VERSION ""

NS_ :

BS_:

BU_: TC CGM VCU TOOL

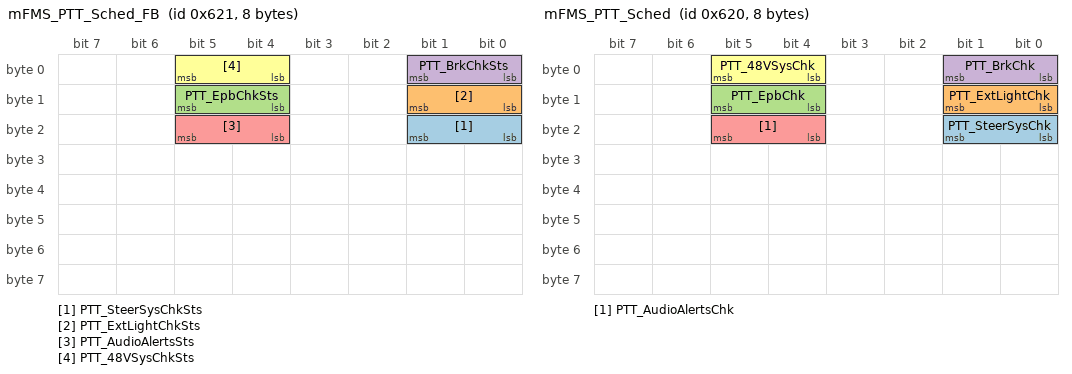
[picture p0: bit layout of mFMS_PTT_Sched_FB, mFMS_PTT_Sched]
BO_ 1569 mFMS_PTT_Sched_FB: 8 VCU
 SG_ PTT_SteerSysChkSts : 17|2@0+ (1,0) [0|3] ""  CGM
 SG_ PTT_ExtLightChkSts : 9|2@0+ (1,0) [0|3] ""  CGM
 SG_ PTT_EpbChkSts : 13|2@0+ (1,0) [0|3] ""  CGM
 SG_ PTT_BrkChkSts : 1|2@0+ (1,0) [0|3] ""  CGM
 SG_ PTT_AudioAlertsSts : 21|2@0+ (1,0) [0|3] ""  CGM
 SG_ PTT_48VSysChkSts : 5|2@0+ (1,0) [0|3] ""  CGM

BO_ 1568 mFMS_PTT_Sched: 8 CGM
 SG_ PTT_SteerSysChk : 17|2@0+ (1,0) [0|3] ""  VCU
 SG_ PTT_ExtLightChk : 9|2@0+ (1,0) [0|3] ""  VCU
 SG_ PTT_EpbChk : 13|2@0+ (1,0) [0|3] ""  VCU
 SG_ PTT_BrkChk : 1|2@0+ (1,0) [0|3] ""  VCU
 SG_ PTT_AudioAlertsChk : 21|2@0+ (1,0) [0|3] ""  VCU
 SG_ PTT_48VSysChk : 5|2@0+ (1,0) [0|3] ""  VCU

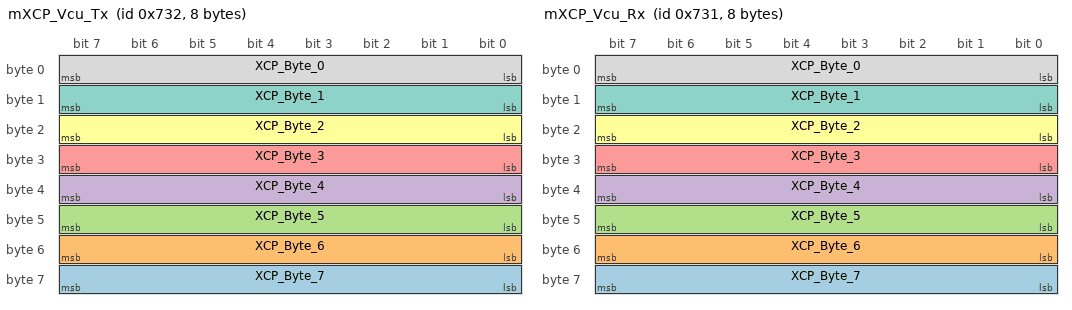
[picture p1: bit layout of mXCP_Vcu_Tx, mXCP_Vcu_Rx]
BO_ 1842 mXCP_Vcu_Tx: 8 VCU
 SG_ XCP_Byte_7 : 63|8@0+ (1,0) [0|0] ""  TOOL
 SG_ XCP_Byte_6 : 55|8@0+ (1,0) [0|0] ""  TOOL
 SG_ XCP_Byte_5 : 47|8@0+ (1,0) [0|0] ""  TOOL
 SG_ XCP_Byte_4 : 39|8@0+ (1,0) [0|0] ""  TOOL
 SG_ XCP_Byte_3 : 31|8@0+ (1,0) [0|0] ""  TOOL
 SG_ XCP_Byte_2 : 23|8@0+ (1,0) [0|0] ""  TOOL
 SG_ XCP_Byte_1 : 15|8@0+ (1,0) [0|0] ""  TOOL
 SG_ XCP_Byte_0 : 7|8@0+ (1,0) [0|0] ""  TOOL

BO_ 1841 mXCP_Vcu_Rx: 8 TOOL
 SG_ XCP_Byte_7 : 63|8@0+ (1,0) [0|0] ""  VCU
 SG_ XCP_Byte_6 : 55|8@0+ (1,0) [0|0] ""  VCU
 SG_ XCP_Byte_5 : 47|8@0+ (1,0) [0|0] ""  VCU
 SG_ XCP_Byte_4 : 39|8@0+ (1,0) [0|0] ""  VCU
 SG_ XCP_Byte_3 : 31|8@0+ (1,0) [0|0] ""  VCU
 SG_ XCP_Byte_2 : 23|8@0+ (1,0) [0|0] ""  VCU
 SG_ XCP_Byte_1 : 15|8@0+ (1,0) [0|0] ""  VCU
 SG_ XCP_Byte_0 : 7|8@0+ (1,0) [0|0] ""  VCU

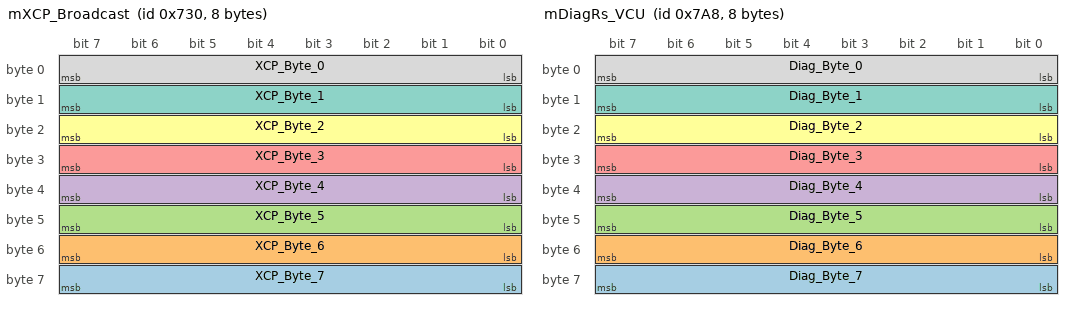
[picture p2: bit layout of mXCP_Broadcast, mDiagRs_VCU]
BO_ 1840 mXCP_Broadcast: 8 TOOL
 SG_ XCP_Byte_7 : 63|8@0+ (1,0) [0|0] ""  VCU
 SG_ XCP_Byte_6 : 55|8@0+ (1,0) [0|0] ""  VCU
 SG_ XCP_Byte_5 : 47|8@0+ (1,0) [0|0] ""  VCU
 SG_ XCP_Byte_4 : 39|8@0+ (1,0) [0|0] ""  VCU
 SG_ XCP_Byte_3 : 31|8@0+ (1,0) [0|0] ""  VCU
 SG_ XCP_Byte_2 : 23|8@0+ (1,0) [0|0] ""  VCU
 SG_ XCP_Byte_1 : 15|8@0+ (1,0) [0|0] ""  VCU
 SG_ XCP_Byte_0 : 7|8@0+ (1,0) [0|0] ""  VCU

BO_ 1960 mDiagRs_VCU: 8 VCU
 SG_ Diag_Byte_7 : 63|8@0+ (1,0) [0|0] ""  TOOL
 SG_ Diag_Byte_6 : 55|8@0+ (1,0) [0|0] ""  TOOL
 SG_ Diag_Byte_5 : 47|8@0+ (1,0) [0|0] ""  TOOL
 SG_ Diag_Byte_4 : 39|8@0+ (1,0) [0|0] ""  TOOL
 SG_ Diag_Byte_3 : 31|8@0+ (1,0) [0|0] ""  TOOL
 SG_ Diag_Byte_2 : 23|8@0+ (1,0) [0|0] ""  TOOL
 SG_ Diag_Byte_1 : 15|8@0+ (1,0) [0|0] ""  TOOL
 SG_ Diag_Byte_0 : 7|8@0+ (1,0) [0|0] ""  TOOL

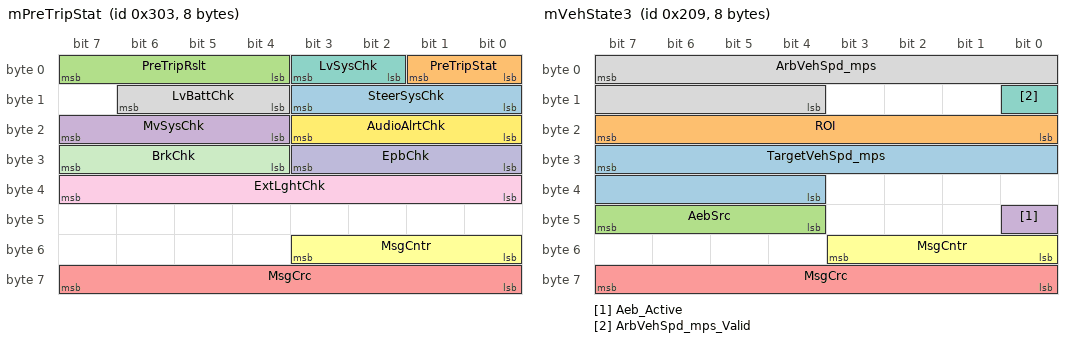
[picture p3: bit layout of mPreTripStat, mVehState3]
BO_ 771 mPreTripStat: 8 VCU
 SG_ SteerSysChk : 11|4@0+ (1,0) [0|15] ""  CGM
 SG_ PreTripStat : 1|2@0+ (1,0) [0|3] ""  CGM
 SG_ PreTripRslt : 7|4@0+ (1,0) [0|15] ""  CGM
 SG_ MvSysChk : 23|4@0+ (1,0) [0|15] ""  CGM
 SG_ MsgCrc : 63|8@0+ (1,0) [0|255] ""  CGM
 SG_ MsgCntr : 51|4@0+ (1,0) [0|15] ""  CGM
 SG_ LvSysChk : 3|2@0+ (1,0) [0|3] ""  CGM
 SG_ LvBattChk : 14|3@0+ (1,0) [0|7] ""  CGM
 SG_ ExtLghtChk : 39|8@0+ (1,0) [0|255] ""  CGM
 SG_ EpbChk : 27|4@0+ (1,0) [0|15] ""  CGM
 SG_ BrkChk : 31|4@0+ (1,0) [0|15] ""  CGM
 SG_ AudioAlrtChk : 19|4@0+ (1,0) [0|15] ""  CGM

BO_ 521 mVehState3: 8 VCU
 SG_ TargetVehSpd_mps : 31|12@0- (0.01,0) [-20.48|20.47] "mps"  CGM
 SG_ ROI : 23|8@0- (0.01,0) [-1.28|1.27] ""  CGM
 SG_ AebSrc : 47|4@0+ (1,0) [0|15] ""  CGM
 SG_ Aeb_Active : 40|1@0+ (1,0) [0|0] ""  CGM
 SG_ MsgCrc : 63|8@0+ (1,0) [0|255] ""  CGM
 SG_ MsgCntr : 51|4@0+ (1,0) [0|15] ""  CGM
 SG_ ArbVehSpd_mps_Valid : 8|1@0+ (1,0) [0|0] ""  CGM
 SG_ ArbVehSpd_mps : 7|12@0- (0.01,0) [-20.48|20.47] "mps"  CGM

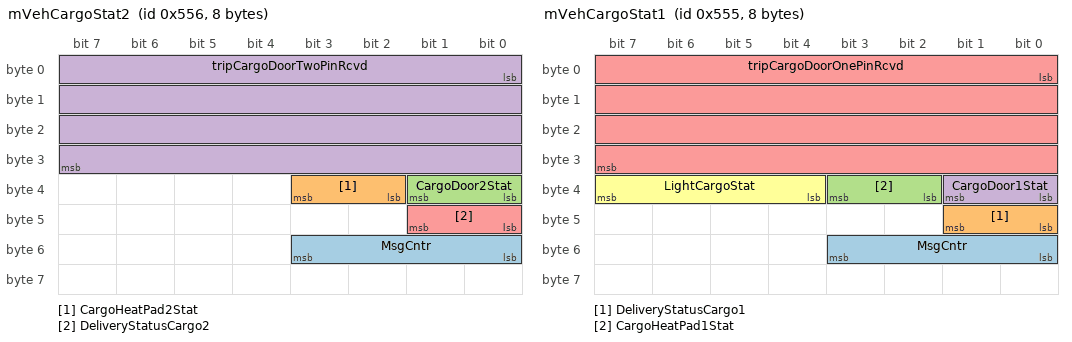
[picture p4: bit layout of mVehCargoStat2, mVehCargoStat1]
BO_ 1366 mVehCargoStat2: 8 VCU
 SG_ MsgCntr : 51|4@0+ (1,0) [0|15] ""  CGM
 SG_ CargoHeatPad2Stat : 35|2@0+ (1,0) [0|3] ""  CGM
 SG_ CargoDoor2Stat : 33|2@0+ (1,0) [0|3] ""  CGM
 SG_ tripCargoDoorTwoPinRcvd : 0|32@1+ (1,0) [0|0] "BCD"  CGM
 SG_ DeliveryStatusCargo2 : 41|2@0+ (1,0) [0|0] ""  CGM

BO_ 1365 mVehCargoStat1: 8 VCU
 SG_ MsgCntr : 51|4@0+ (1,0) [0|15] ""  CGM
 SG_ DeliveryStatusCargo1 : 41|2@0+ (1,0) [0|0] ""  CGM
 SG_ CargoHeatPad1Stat : 35|2@0+ (1,0) [0|3] ""  CGM
 SG_ CargoDoor1Stat : 33|2@0+ (1,0) [0|3] ""  CGM
 SG_ tripCargoDoorOnePinRcvd : 0|32@1+ (1,0) [0|0] "BCD"  CGM
 SG_ LightCargoStat : 39|4@0+ (1,0) [0|15] ""  CGM

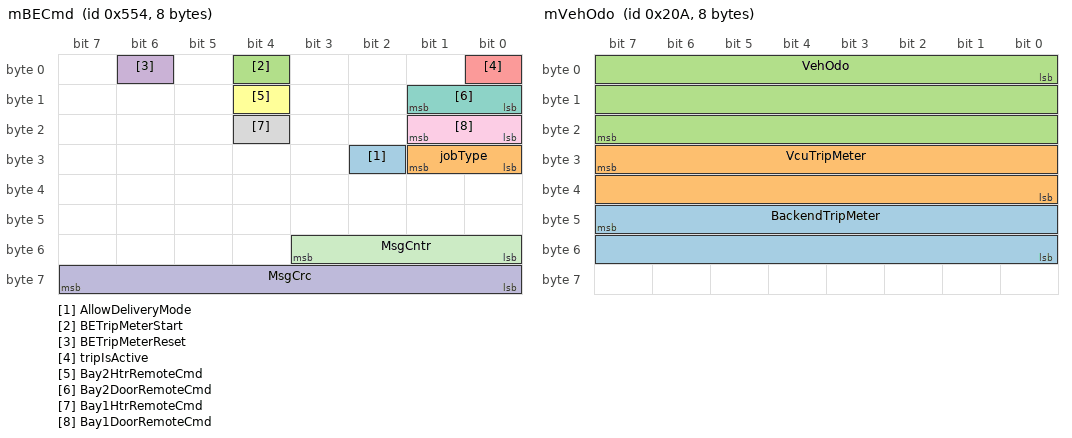
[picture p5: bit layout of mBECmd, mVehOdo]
BO_ 1364 mBECmd: 8 CGM
 SG_ AllowDeliveryMode : 26|1@0+ (1,0) [0|1] ""  VCU
 SG_ jobType : 25|2@0+ (1,0) [0|3] ""  VCU
 SG_ BETripMeterStart : 4|1@0+ (1,0) [0|0] ""  VCU
 SG_ BETripMeterReset : 6|1@0+ (1,0) [0|0] ""  VCU
 SG_ tripIsActive : 0|1@0+ (1,0) [0|0] ""  VCU
 SG_ Bay2HtrRemoteCmd : 12|1@0+ (1,0) [0|1] ""  VCU
 SG_ Bay2DoorRemoteCmd : 9|2@0+ (1,0) [0|3] ""  VCU
 SG_ Bay1HtrRemoteCmd : 20|1@0+ (1,0) [0|1] ""  VCU
 SG_ Bay1DoorRemoteCmd : 17|2@0+ (1,0) [0|3] ""  VCU
 SG_ MsgCrc : 63|8@0+ (1,0) [0|255] ""  VCU
 SG_ MsgCntr : 51|4@0+ (1,0) [0|15] ""  VCU

BO_ 1363 mBECargoPIN: 8 CGM
 SG_ tripCargoDoorTwoPin : 32|32@1+ (1,0) [0|0] "BCD"  VCU
 SG_ tripCargoDoorOnePin : 0|32@1+ (1,0) [0|0] "BCD"  VCU

BO_ 522 mVehOdo: 8 VCU
 SG_ BackendTripMeter : 47|16@0+ (0.001,0) [0|65.535] "Km"  CGM
 SG_ VcuTripMeter : 31|16@0+ (0.001,0) [0|65.535] "Km"  CGM
 SG_ VehOdo : 0|24@1+ (0.001,0) [0|16777.213] "Km"  CGM

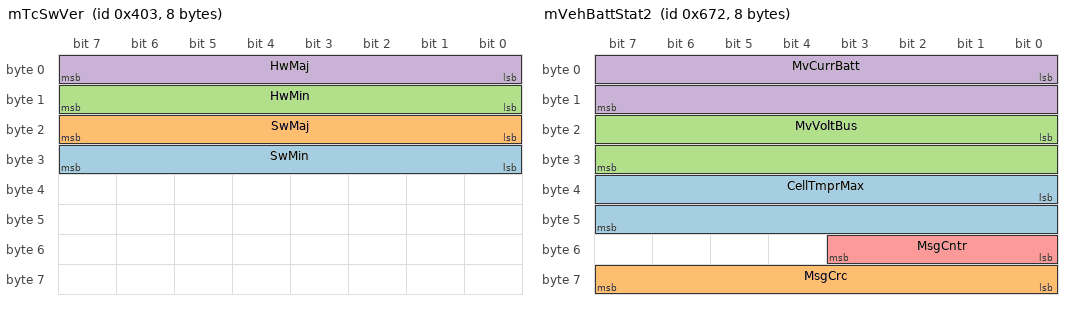
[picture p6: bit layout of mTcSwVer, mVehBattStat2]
BO_ 1027 mTcSwVer: 8 TC
 SG_ SwMin : 31|8@0+ (1,0) [0|255] ""  VCU
 SG_ SwMaj : 23|8@0+ (1,0) [0|255] ""  VCU
 SG_ HwMin : 15|8@0+ (1,0) [0|255] ""  VCU
 SG_ HwMaj : 7|8@0+ (1,0) [0|255] ""  VCU

BO_ 1650 mVehBattStat2: 8 VCU
 SG_ CellTmprMax : 32|16@1+ (0.03125,-273) [-273|1734.96875] "degC"  CGM
 SG_ MsgCrc : 63|8@0+ (1,0) [0|255] ""  CGM
 SG_ MvVoltBus : 16|16@1+ (0.05,0) [0|3212.75] "V"  CGM
 SG_ MvCurrBatt : 0|16@1+ (0.05,-1600) [-1600|1612.75] "A"  CGM
 SG_ MsgCntr : 51|4@0+ (1,0) [0|15] ""  CGM

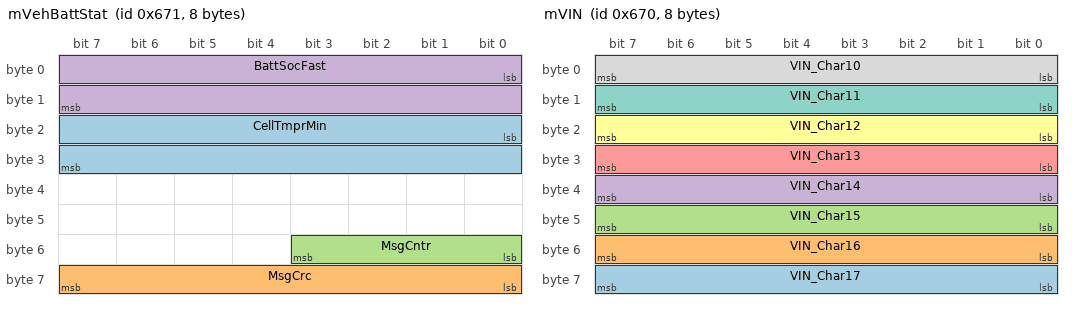
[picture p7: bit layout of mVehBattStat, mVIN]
BO_ 1649 mVehBattStat: 8 VCU
 SG_ CellTmprMin : 16|16@1+ (0.03125,-273) [-273|1734.96875] "degC"  CGM
 SG_ MsgCrc : 63|8@0+ (1,0) [0|255] ""  CGM
 SG_ MsgCntr : 51|4@0+ (1,0) [0|15] ""  CGM
 SG_ BattSocFast : 0|16@1+ (0.0015625,0) [0|100.3984375] "%"  CGM

BO_ 1648 mVIN: 8 VCU
 SG_ VIN_Char17 : 63|8@0+ (1,0) [0|255] "ASCII"  CGM
 SG_ VIN_Char16 : 55|8@0+ (1,0) [0|255] "ASCII"  CGM
 SG_ VIN_Char15 : 47|8@0+ (1,0) [0|255] "ASCII"  CGM
 SG_ VIN_Char14 : 39|8@0+ (1,0) [0|255] "ASCII"  CGM
 SG_ VIN_Char13 : 31|8@0+ (1,0) [0|255] "ASCII"  CGM
 SG_ VIN_Char12 : 23|8@0+ (1,0) [0|255] "ASCII"  CGM
 SG_ VIN_Char11 : 15|8@0+ (1,0) [0|255] "ASCII"  CGM
 SG_ VIN_Char10 : 7|8@0+ (1,0) [0|255] "ASCII"  CGM

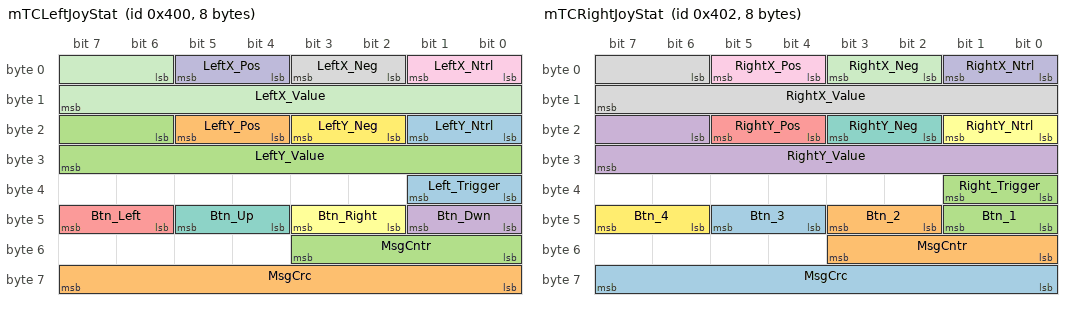
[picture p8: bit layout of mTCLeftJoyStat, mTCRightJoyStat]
BO_ 1024 mTCLeftJoyStat: 8 TC
 SG_ Left_Trigger : 32|2@1+ (1,0) [0|3] ""  VCU
 SG_ MsgCrc : 63|8@0+ (1,0) [0|255] ""  VCU
 SG_ MsgCntr : 51|4@0+ (1,0) [0|15] ""  VCU
 SG_ Btn_Dwn : 40|2@1+ (1,0) [0|3] ""  VCU
 SG_ Btn_Left : 46|2@1+ (1,0) [0|3] ""  VCU
 SG_ Btn_Right : 42|2@1+ (1,0) [0|3] ""  VCU
 SG_ Btn_Up : 44|2@1+ (1,0) [0|3] ""  VCU
 SG_ LeftX_Neg : 2|2@1+ (1,0) [0|3] ""  VCU
 SG_ LeftX_Ntrl : 0|2@1+ (1,0) [0|3] ""  VCU
 SG_ LeftX_Pos : 4|2@1+ (1,0) [0|3] ""  VCU
 SG_ LeftX_Value : 6|10@1+ (1,0) [0|1023] ""  VCU
 SG_ LeftY_Neg : 18|2@1+ (1,0) [0|3] ""  VCU
 SG_ LeftY_Ntrl : 16|2@1+ (1,0) [0|3] ""  VCU
 SG_ LeftY_Pos : 20|2@1+ (1,0) [0|3] ""  VCU
 SG_ LeftY_Value : 22|10@1+ (1,0) [0|1023] ""  VCU

BO_ 1026 mTCRightJoyStat: 8 TC
 SG_ MsgCrc : 63|8@0+ (1,0) [0|255] ""  VCU
 SG_ MsgCntr : 51|4@0+ (1,0) [0|15] ""  VCU
 SG_ Right_Trigger : 32|2@1+ (1,0) [0|3] ""  VCU
 SG_ RightY_Value : 22|10@1+ (1,0) [0|1023] ""  VCU
 SG_ RightY_Pos : 20|2@1+ (1,0) [0|3] ""  VCU
 SG_ RightY_Ntrl : 16|2@1+ (1,0) [0|3] ""  VCU
 SG_ RightY_Neg : 18|2@1+ (1,0) [0|3] ""  VCU
 SG_ RightX_Value : 6|10@1+ (1,0) [0|1023] ""  VCU
 SG_ RightX_Pos : 4|2@1+ (1,0) [0|3] ""  VCU
 SG_ RightX_Ntrl : 0|2@1+ (1,0) [0|3] ""  VCU
 SG_ RightX_Neg : 2|2@1+ (1,0) [0|3] ""  VCU
 SG_ Btn_4 : 46|2@1+ (1,0) [0|3] ""  VCU
 SG_ Btn_3 : 44|2@1+ (1,0) [0|3] ""  VCU
 SG_ Btn_2 : 42|2@1+ (1,0) [0|3] ""  VCU
 SG_ Btn_1 : 40|2@1+ (1,0) [0|3] ""  VCU

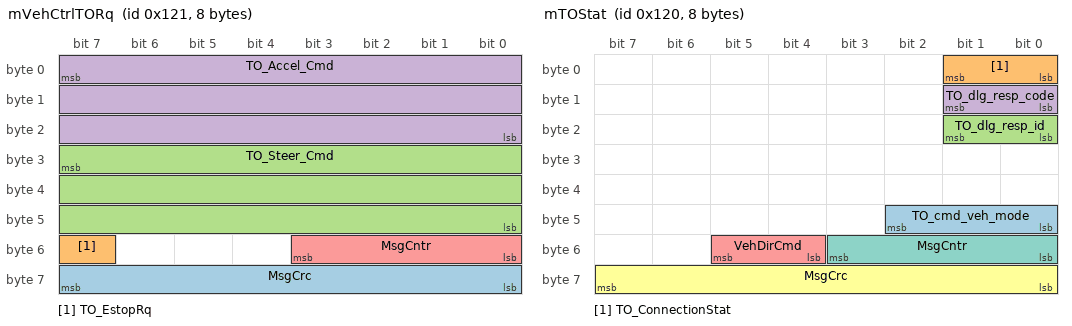
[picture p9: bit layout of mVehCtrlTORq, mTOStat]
BO_ 289 mVehCtrlTORq: 8 CGM
 SG_ MsgCrc : 63|8@0+ (1,0) [0|255] ""  VCU
 SG_ TO_EstopRq : 55|1@0+ (1,0) [0|1] ""  VCU
 SG_ TO_Steer_Cmd : 31|24@0- (1E-06,0) [-1|1] ""  VCU
 SG_ TO_Accel_Cmd : 7|24@0- (1E-06,0) [-1|1] ""  VCU
 SG_ MsgCntr : 51|4@0+ (1,0) [0|15] ""  VCU

BO_ 288 mTOStat: 8 CGM
 SG_ TO_cmd_veh_mode : 42|3@0+ (1,0) [0|7] ""  VCU
 SG_ TO_ConnectionStat : 1|2@0+ (1,0) [0|2] ""  VCU
 SG_ TO_dlg_resp_id : 17|2@0+ (1,0) [0|3] ""  VCU
 SG_ TO_dlg_resp_code : 9|2@0+ (1,0) [0|3] ""  VCU
 SG_ VehDirCmd : 53|2@0+ (1,0) [0|0] ""  VCU
 SG_ MsgCrc : 63|8@0+ (1,0) [0|255] ""  VCU
 SG_ MsgCntr : 51|4@0+ (1,0) [0|15] ""  VCU

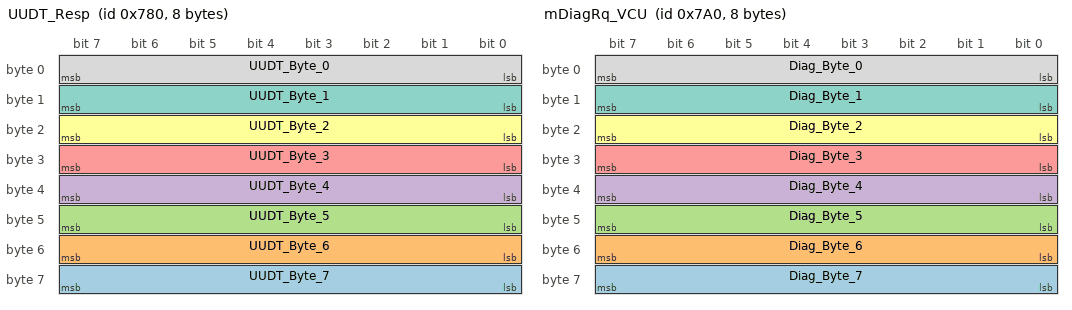
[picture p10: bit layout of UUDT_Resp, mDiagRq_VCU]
BO_ 1920 UUDT_Resp: 8 VCU
 SG_ UUDT_Byte_7 : 63|8@0+ (1,0) [0|0] ""  TOOL
 SG_ UUDT_Byte_6 : 55|8@0+ (1,0) [0|0] ""  TOOL
 SG_ UUDT_Byte_5 : 47|8@0+ (1,0) [0|0] ""  TOOL
 SG_ UUDT_Byte_4 : 39|8@0+ (1,0) [0|0] ""  TOOL
 SG_ UUDT_Byte_3 : 31|8@0+ (1,0) [0|0] ""  TOOL
 SG_ UUDT_Byte_2 : 23|8@0+ (1,0) [0|0] ""  TOOL
 SG_ UUDT_Byte_1 : 15|8@0+ (1,0) [0|0] ""  TOOL
 SG_ UUDT_Byte_0 : 7|8@0+ (1,0) [0|0] ""  TOOL

BO_ 1952 mDiagRq_VCU: 8 TOOL
 SG_ Diag_Byte_7 : 63|8@0+ (1,0) [0|0] ""  VCU
 SG_ Diag_Byte_6 : 55|8@0+ (1,0) [0|0] ""  VCU
 SG_ Diag_Byte_5 : 47|8@0+ (1,0) [0|0] ""  VCU
 SG_ Diag_Byte_4 : 39|8@0+ (1,0) [0|0] ""  VCU
 SG_ Diag_Byte_3 : 31|8@0+ (1,0) [0|0] ""  VCU
 SG_ Diag_Byte_2 : 23|8@0+ (1,0) [0|0] ""  VCU
 SG_ Diag_Byte_1 : 15|8@0+ (1,0) [0|0] ""  VCU
 SG_ Diag_Byte_0 : 7|8@0+ (1,0) [0|0] ""  VCU

BO_ 1160 mVcuHeartbeat: 8 VCU
 SG_ seconds : 7|32@0- (1,0) [-2147483648|2147483647] "s"  CGM
 SG_ nanoseconds : 39|32@0+ (1,0) [0|4294967295] "ns"  CGM

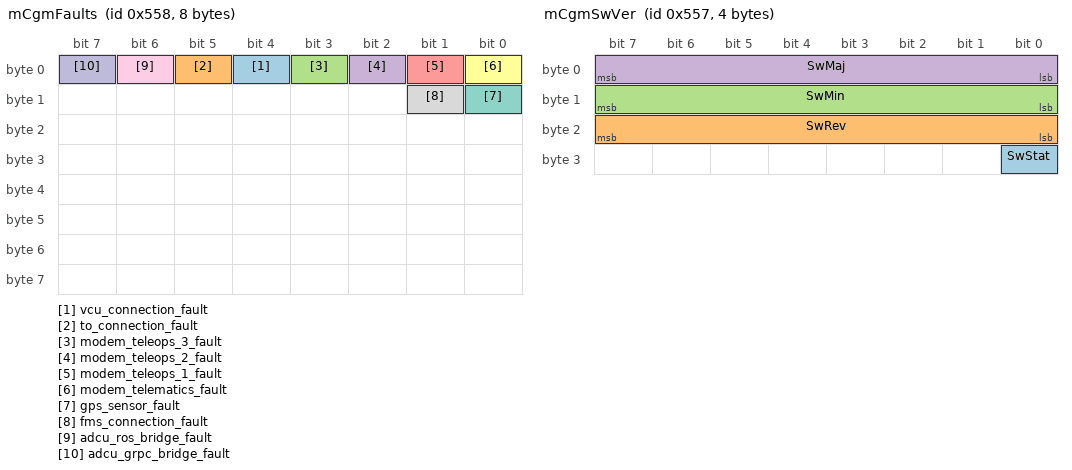
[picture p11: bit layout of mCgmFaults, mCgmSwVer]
BO_ 1368 mCgmFaults: 8 CGM
 SG_ vcu_connection_fault : 4|1@0+ (1,0) [0|0] ""  VCU
 SG_ to_connection_fault : 5|1@0+ (1,0) [0|0] ""  VCU
 SG_ modem_teleops_3_fault : 3|1@0+ (1,0) [0|0] ""  VCU
 SG_ modem_teleops_2_fault : 2|1@0+ (1,0) [0|0] ""  VCU
 SG_ modem_teleops_1_fault : 1|1@0+ (1,0) [0|0] ""  VCU
 SG_ modem_telematics_fault : 0|1@0+ (1,0) [0|0] ""  VCU
 SG_ gps_sensor_fault : 8|1@0+ (1,0) [0|0] ""  VCU
 SG_ fms_connection_fault : 9|1@0+ (1,0) [0|0] ""  VCU
 SG_ adcu_ros_bridge_fault : 6|1@0+ (1,0) [0|0] ""  VCU
 SG_ adcu_grpc_bridge_fault : 7|1@0+ (1,0) [0|0] ""  VCU

BO_ 528 mCgmHeartbeat: 8 CGM
 SG_ seconds : 7|32@0- (1,0) [-2147483648|2147483647] "s"  VCU
 SG_ nanoseconds : 39|32@0+ (1,0) [0|4294967295] "ns"  VCU

BO_ 1367 mCgmSwVer: 4 CGM
 SG_ SwStat : 24|1@0+ (1,0) [0|1] ""  VCU
 SG_ SwRev : 23|8@0+ (1,0) [0|255] ""  VCU
 SG_ SwMin : 15|8@0+ (1,0) [0|255] ""  VCU
 SG_ SwMaj : 7|8@0+ (1,0) [0|255] ""  VCU

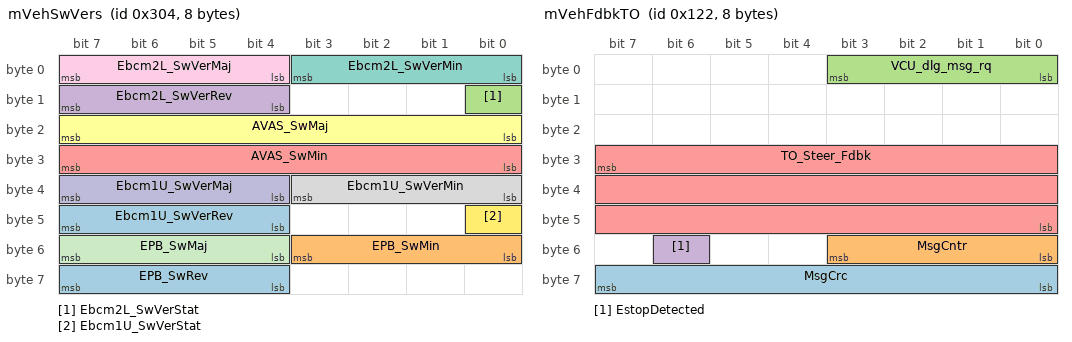
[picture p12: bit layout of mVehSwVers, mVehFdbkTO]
BO_ 772 mVehSwVers: 8 VCU
 SG_ EPB_SwRev : 63|4@0+ (1,0) [0|15] ""  CGM
 SG_ EPB_SwMin : 51|4@0+ (1,0) [0|15] ""  CGM
 SG_ Ebcm2L_SwVerStat : 8|1@0+ (1,0) [0|1] ""  CGM
 SG_ Ebcm2L_SwVerRev : 15|4@0+ (1,0) [0|15] ""  CGM
 SG_ AVAS_SwMin : 31|8@0+ (1,0) [0|255] ""  CGM
 SG_ AVAS_SwMaj : 23|8@0+ (1,0) [0|255] ""  CGM
 SG_ Ebcm2L_SwVerMin : 3|4@0+ (1,0) [0|15] ""  CGM
 SG_ Ebcm1U_SwVerMin : 35|4@0+ (1,0) [0|15] ""  CGM
 SG_ Ebcm2L_SwVerMaj : 7|4@0+ (1,0) [0|15] ""  CGM
 SG_ Ebcm1U_SwVerMaj : 39|4@0+ (1,0) [0|15] ""  CGM
 SG_ EPB_SwMaj : 55|4@0+ (1,0) [0|15] ""  CGM
 SG_ Ebcm1U_SwVerStat : 40|1@0+ (1,0) [0|1] ""  CGM
 SG_ Ebcm1U_SwVerRev : 47|4@0+ (1,0) [0|15] ""  CGM

BO_ 290 mVehFdbkTO: 8 VCU
 SG_ MsgCrc : 63|8@0+ (1,0) [0|255] ""  CGM
 SG_ MsgCntr : 51|4@0+ (1,0) [0|15] ""  CGM
 SG_ VCU_dlg_msg_rq : 3|4@0+ (1,0) [0|15] ""  CGM
 SG_ EstopDetected : 54|1@0+ (1,0) [0|1] ""  CGM
 SG_ TO_Steer_Fdbk : 31|24@0- (1E-06,0) [-1|1] ""  CGM

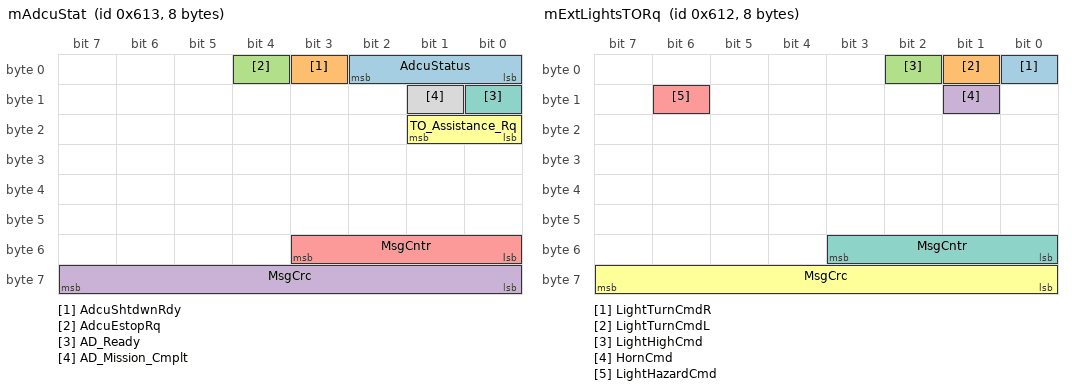
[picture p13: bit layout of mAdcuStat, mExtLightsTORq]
BO_ 1555 mAdcuStat: 8 VCU
 SG_ AdcuStatus : 2|3@0+ (1,0) [0|7] ""  CGM
 SG_ AdcuShtdwnRdy : 3|1@0+ (1,0) [0|1] ""  CGM
 SG_ AdcuEstopRq : 4|1@0+ (1,0) [0|1] ""  CGM
 SG_ MsgCrc : 63|8@0+ (1,0) [0|255] ""  CGM
 SG_ MsgCntr : 51|4@0+ (1,0) [0|15] ""  CGM
 SG_ TO_Assistance_Rq : 17|2@0+ (1,0) [0|2] ""  CGM
 SG_ AD_Ready : 8|1@0+ (1,0) [0|0] ""  CGM
 SG_ AD_Mission_Cmplt : 9|1@0+ (1,0) [0|1] ""  CGM

BO_ 1554 mExtLightsTORq: 8 CGM
 SG_ LightTurnCmdR : 0|1@1+ (1,0) [0|1] ""  VCU
 SG_ LightTurnCmdL : 1|1@1+ (1,0) [0|1] ""  VCU
 SG_ LightHighCmd : 2|1@1+ (1,0) [0|1] ""  VCU
 SG_ HornCmd : 9|1@1+ (1,0) [0|1] ""  VCU
 SG_ LightHazardCmd : 14|1@0+ (1,0) [0|1] ""  VCU
 SG_ MsgCrc : 63|8@0+ (1,0) [0|255] ""  VCU
 SG_ MsgCntr : 51|4@0+ (1,0) [0|15] ""  VCU

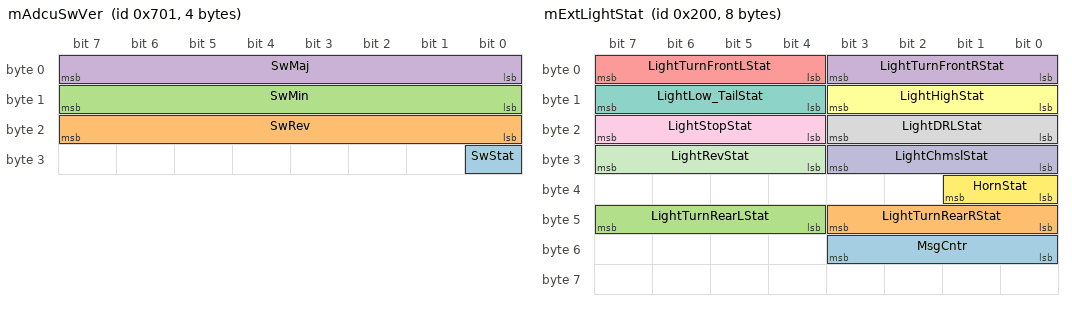
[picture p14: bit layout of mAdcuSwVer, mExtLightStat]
BO_ 1793 mAdcuSwVer: 4 VCU
 SG_ SwStat : 24|1@0+ (1,0) [0|1] ""  CGM
 SG_ SwRev : 23|8@0+ (1,0) [0|255] ""  CGM
 SG_ SwMin : 15|8@0+ (1,0) [0|255] ""  CGM
 SG_ SwMaj : 7|8@0+ (1,0) [0|255] ""  CGM

BO_ 516 mVcuFaults: 8 VCU
 SG_ Flt_InvalidGearRq : 61|1@0+ (1,0) [0|1] ""  CGM
 SG_ Flt_LocEpb : 54|2@1+ (1,0) [0|3] ""  CGM
 SG_ Flt_LocTo : 34|2@1+ (1,0) [0|3] ""  CGM
 SG_ Flt_LocBe : 32|2@1+ (1,0) [0|3] ""  CGM
 SG_ Flt_12vSys : 26|1@1+ (1,0) [0|1] ""  CGM
 SG_ Flt_WriteEeprom : 24|1@1+ (1,0) [0|1] ""  CGM
 SG_ Flt_ReadEeprom : 25|1@1+ (1,0) [0|1] ""  CGM
 SG_ Flt_BrkSafeSys : 58|1@1+ (1,0) [0|1] ""  CGM
 SG_ Flt_SafeCircuit : 5|1@1+ (1,0) [0|1] ""  CGM
 SG_ Flt_MstrSwitch : 4|1@1+ (1,0) [0|1] ""  CGM
 SG_ Flt_CntctrStat : 59|2@1+ (1,0) [0|1] ""  CGM
 SG_ Flt_BrkPrsr : 56|1@1+ (1,0) [0|1] ""  CGM
 SG_ Flt_WhdEnbl : 62|1@1+ (1,0) [0|1] ""  CGM
 SG_ Flt_SbwEnbl : 47|1@1+ (1,0) [0|1] ""  CGM
 SG_ Flt_SafeSteer : 52|2@1+ (1,0) [0|3] ""  CGM
 SG_ Flt_SafeProp : 50|2@1+ (1,0) [0|3] ""  CGM
 SG_ Flt_SafeExtLight : 48|2@1+ (1,0) [0|3] ""  CGM
 SG_ Flt_EpbSys : 57|1@1+ (1,0) [0|1] ""  CGM
 SG_ Flt_DcdcEnbl : 63|1@1+ (1,0) [0|1] ""  CGM
 SG_ Flt_48Volt : 2|2@1+ (1,0) [0|3] ""  CGM
 SG_ Flt_12Volt : 0|2@1+ (1,0) [0|3] ""  CGM
 SG_ Flt_LocWhd : 6|2@1+ (1,0) [0|3] ""  CGM
 SG_ Flt_LocTc : 22|2@1+ (1,0) [0|3] ""  CGM
 SG_ Flt_LocSbw : 20|2@1+ (1,0) [0|3] ""  CGM
 SG_ Flt_LocAVAS : 18|2@1+ (1,0) [0|3] ""  CGM
 SG_ Flt_LocVsc : 16|2@1+ (1,0) [0|3] ""  CGM
 SG_ Flt_LocEss : 14|2@1+ (1,0) [0|3] ""  CGM
 SG_ Flt_LocEbcm2 : 12|2@1+ (1,0) [0|3] ""  CGM
 SG_ Flt_LocEbcm1 : 10|2@1+ (1,0) [0|3] ""  CGM
 SG_ Flt_LocAdcu : 8|2@1+ (1,0) [0|3] ""  CGM
 SG_ Flt_LocLrr : 40|1@1+ (1,0) [0|1] ""  CGM
 SG_ Flt_KeypadLight : 46|1@1+ (1,0) [0|1] ""  CGM
 SG_ Flt_KeypadC : 45|1@1+ (1,0) [0|1] ""  CGM
 SG_ Flt_Keypad4 : 44|1@1+ (1,0) [0|1] ""  CGM
 SG_ Flt_LocFcmCan : 43|1@1+ (1,0) [0|1] ""  CGM
 SG_ Flt_ImuRst : 42|1@1+ (1,0) [0|1] ""  CGM
 SG_ Flt_ImuSns : 41|1@1+ (1,0) [0|1] ""  CGM
 SG_ Flt_Bay2Pwr12v : 39|1@1+ (1,0) [0|1] ""  CGM
 SG_ Flt_Bay2MtrPos : 37|1@1+ (1,0) [0|1] ""  CGM
 SG_ Flt_Bay2Mtr : 38|1@1+ (1,0) [0|1] ""  CGM
 SG_ Flt_Bay2BeltSns : 36|1@1+ (1,0) [0|1] ""  CGM
 SG_ Flt_Bay1Pwr12v : 31|1@1+ (1,0) [0|1] ""  CGM
 SG_ Flt_Bay1MtrPos : 29|1@1+ (1,0) [0|1] ""  CGM
 SG_ Flt_Bay1Mtr : 30|1@1+ (1,0) [0|1] ""  CGM
 SG_ Flt_Bay1BeltSns : 28|1@1+ (1,0) [0|1] ""  CGM

BO_ 514 mVehState: 8 VCU
 SG_ SBW_RtEndStopReached : 28|1@0+ (1,0) [0|1] ""  CGM
 SG_ SBW_LfEndStopReached : 29|1@0+ (1,0) [0|1] ""  CGM
 SG_ Invld_GearRq : 55|1@0+ (1,0) [0|1] ""  CGM
 SG_ EstopDetected : 41|1@0+ (1,0) [0|1] ""  CGM
 SG_ Tether_Connected : 43|1@0+ (1,0) [0|0] ""  CGM
 SG_ VehParkRq : 42|1@0- (1,0) [0|0] ""  CGM
 SG_ ArbVehSpdValid : 40|1@0+ (1,0) [0|0] ""  CGM
 SG_ ArbVehSpd : 39|12@0- (0.02,0) [-40.96|40.94] "kph"  CGM
 SG_ GearRq : 24|2@1+ (1,0) [0|3] ""  CGM
 SG_ GearChangeParkAllow : 30|1@0+ (1,0) [0|0] ""  CGM
 SG_ TO_Allowed : 52|1@0+ (1,0) [0|0] ""  CGM
 SG_ LOS_Allowed : 54|1@0+ (1,0) [0|0] ""  CGM
 SG_ AD_Allowed : 53|1@0+ (1,0) [0|0] ""  CGM
 SG_ GearChangeDrvRevAllow : 31|1@0+ (1,0) [0|0] ""  CGM
 SG_ GearAct : 26|2@1+ (1,0) [0|3] ""  CGM
 SG_ MsgCrc : 63|8@0+ (1,0) [0|255] ""  CGM
 SG_ MsgCntr : 48|4@1+ (1,0) [0|15] ""  CGM
 SG_ VehDte : 6|10@1+ (0.1,0) [0|102.3] "Km"  CGM
 SG_ LvVolt : 16|8@1+ (0.1,0) [0|25.5] "V"  CGM
 SG_ CrashSns : 5|1@1+ (1,0) [0|1] ""  CGM
 SG_ VcuEstopSns : 4|1@1+ (1,0) [0|1] ""  CGM
 SG_ VehState : 0|4@1+ (1,0) [0|15] ""  CGM

BO_ 512 mExtLightStat: 8 VCU
 SG_ MsgCntr : 51|4@0+ (1,0) [0|15] ""  CGM
 SG_ LightTurnRearRStat : 40|4@1+ (1,0) [0|3] ""  CGM
 SG_ LightTurnRearLStat : 44|4@1+ (1,0) [0|3] ""  CGM
 SG_ LightTurnFrontRStat : 0|4@1+ (1,0) [0|3] ""  CGM
 SG_ LightTurnFrontLStat : 4|4@1+ (1,0) [0|3] ""  CGM
 SG_ LightHighStat : 8|4@1+ (1,0) [0|3] ""  CGM
 SG_ LightLow_TailStat : 12|4@1+ (1,0) [0|3] ""  CGM
 SG_ LightDRLStat : 16|4@1+ (1,0) [0|3] ""  CGM
 SG_ LightStopStat : 20|4@1+ (1,0) [0|3] ""  CGM
 SG_ LightChmslStat : 24|4@1+ (1,0) [0|3] ""  CGM
 SG_ LightRevStat : 28|4@1+ (1,0) [0|3] ""  CGM
 SG_ HornStat : 32|2@1+ (1,0) [0|3] ""  CGM

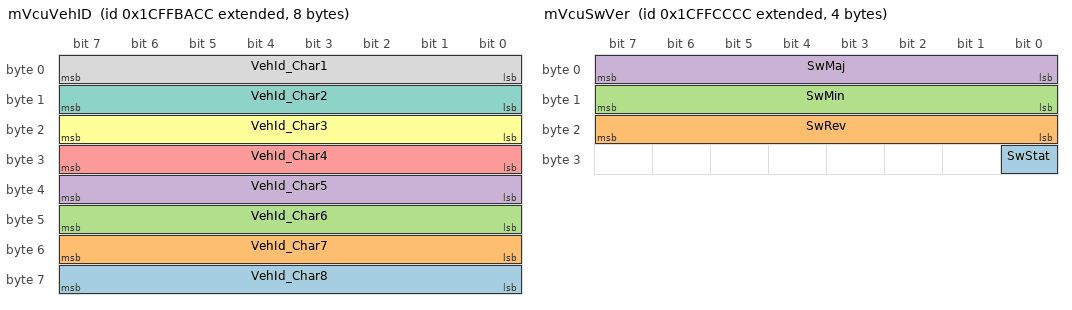
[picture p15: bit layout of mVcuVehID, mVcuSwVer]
BO_ 2634005196 mVcuVehID: 8 VCU
 SG_ VehId_Char8 : 63|8@0+ (1,0) [0|255] "ASCII"  CGM
 SG_ VehId_Char7 : 55|8@0+ (1,0) [0|255] "ASCII"  CGM
 SG_ VehId_Char6 : 47|8@0+ (1,0) [0|255] "ASCII"  CGM
 SG_ VehId_Char5 : 39|8@0+ (1,0) [0|255] "ASCII"  CGM
 SG_ VehId_Char4 : 31|8@0+ (1,0) [0|255] "ASCII"  CGM
 SG_ VehId_Char3 : 23|8@0+ (1,0) [0|255] "ASCII"  CGM
 SG_ VehId_Char2 : 15|8@0+ (1,0) [0|255] "ASCII"  CGM
 SG_ VehId_Char1 : 7|8@0+ (1,0) [0|255] "ASCII"  CGM

BO_ 2634009804 mVcuSwVer: 4 VCU
 SG_ SwStat : 24|1@0+ (1,0) [0|1] ""  CGM
 SG_ SwRev : 23|8@0+ (1,0) [0|255] ""  CGM
 SG_ SwMin : 15|8@0+ (1,0) [0|255] ""  CGM
 SG_ SwMaj : 7|8@0+ (1,0) [0|255] ""  CGM

CM_ BU_ CGM "Autonomous Driving Control Module";
CM_ BU_ VCU "Vehicle Control Unit";
CM_ BU_ TOOL "Generic CAN Tool";
CM_ BO_ 1842 "The DLC of the XCP message in the matrix is only used to generate the DBC file, and the DLC length used in the actual development of the ECU shall meet the technical requirements of the XCP protocol.";
CM_ BO_ 1841 "The DLC of the XCP message in the matrix is only used to generate the DBC file, and the DLC length used in the actual development of the ECU shall meet the technical requirements of the XCP protocol.";
CM_ BO_ 1840 "The DLC of the XCP message in the matrix is only used to generate the DBC file, and the DLC length used in the actual development of the ECU shall meet the technical requirements of the XCP protocol.";
CM_ BO_ 1960 "The DLC of the diagnosis message in the matrix is only used to generate the DBC file, and the DLC length used in the actual development of the ECU shall meet the technical requirements of the UDS.";
CM_ BO_ 771 "Summary of Pre Trip Tests.";
CM_ SG_ 771 SteerSysChk "Result of steering wheel pre trip test";
CM_ SG_ 771 PreTripStat "Reports the pre-trip checks to be performed.";
CM_ SG_ 771 PreTripRslt "General result report for pre-trip tests.
Bitfield.
Bit 0 = SNA / Pass Mandatory
Bit 1 = Fail Mandatory
Bit 2 = Pass Scheduled
Bit 3 = Fail Scheduled";
CM_ SG_ 771 MvSysChk "The result of the 48V System check ";
CM_ SG_ 771 MsgCrc "mPreTripStat Message Checksum (E2E data ID: 0x59)";
CM_ SG_ 771 LvSysChk "The result of the 12V System check (Cannot Disable)";
CM_ SG_ 771 LvBattChk "The result of the 12V Battery check (Cannot Disable)";
CM_ SG_ 771 ExtLghtChk "Result of exterior lights pre trip test.
Bitfield
Bit 0 = SNA/OK
Bit1 = Lowbeam / Tail Lamp / License circuit
Bit2 = Highbeam circuit
Bit3 = Turn Signals
Bit4 = Brake Light
Bit 5 = Not Run - 12V Fault indicator
Bit 7 = Disabled";
CM_ SG_ 771 EpbChk "Result of the Electric Parking Brake pre-trip test";
CM_ SG_ 771 BrkChk "Result of the brake pre-trip test";
CM_ SG_ 771 AudioAlrtChk "Results of audio and horn pre trip test";
CM_ BO_ 521 "Vehicle level data";
CM_ SG_ 521 TargetVehSpd_mps "VCU Arbitrated Vehicle Speed";
CM_ SG_ 521 ROI "Roll Over Index";
CM_ SG_ 521 AebSrc "CGVCU determined source of Aeb Trigger .";
CM_ SG_ 521 Aeb_Active "AEB Event is detected and VCU is actively engaging AEB.";
CM_ SG_ 521 MsgCrc "mVehState3 Message Checksum (E2E data ID: 0x54)";
CM_ SG_ 521 ArbVehSpd_mps_Valid "Validity for Arbitrated Vehicle Speed.";
CM_ SG_ 521 ArbVehSpd_mps "VCU Arbitrated Vehicle Speed";
CM_ BO_ 1366 "Cargo State to CGM / Backend.";
CM_ SG_ 1366 CargoHeatPad2Stat "Status of Cargo Door 1";
CM_ SG_ 1366 CargoDoor2Stat "Status of Cargo Door 1";
CM_ SG_ 1366 tripCargoDoorTwoPinRcvd "Accommodates 1-4 digit codes. All unused digits shall be set to 0xF.  Valid code digits use BCD Encoding.  Example 0x1543 = Code 15432";
CM_ SG_ 1366 DeliveryStatusCargo2 "Cargo Bay 2 delivery status.";
CM_ BO_ 1365 "Cargo State to CGM / Backend.";
CM_ SG_ 1365 DeliveryStatusCargo1 "Cargo Bay 1 delivery status.";
CM_ SG_ 1365 CargoHeatPad1Stat "Status of Cargo Door 1";
CM_ SG_ 1365 CargoDoor1Stat "Status of Cargo Door 1";
CM_ SG_ 1365 tripCargoDoorOnePinRcvd "Accommodates 1-4 digit codes. All unused digits shall be set to 0xF.  Valid code digits use BCD Encoding.  Example 0x1543 = Code 15432";
CM_ BO_ 1364 "Back End Commands";
CM_ SG_ 1364 BETripMeterStart "Start BE Trip Odometer on Rising Edge.";
CM_ SG_ 1364 BETripMeterReset "Reset command for Backend Trip Odometer.";
CM_ SG_ 1364 Bay2HtrRemoteCmd "Cargo Bay 1 heater command.";
CM_ SG_ 1364 Bay2DoorRemoteCmd "Cargo Bay 2 door command.";
CM_ SG_ 1364 Bay1HtrRemoteCmd "Cargo Bay 1 heater command.";
CM_ SG_ 1364 Bay1DoorRemoteCmd "Cargo Bay 1 door command.";
CM_ SG_ 1364 MsgCrc "mFmsCmd Message Checksum (E2E data ID: 0xA5)";
CM_ BO_ 1363 "Cargo PIN numbers from Backend to VCU.";
CM_ SG_ 1363 tripCargoDoorTwoPin "Accommodates 1-4 digit codes. All unused digits shall be set to 0xF.  Valid code digits use BCD Encoding.  Example 0x1543 = Code 15432";
CM_ SG_ 1363 tripCargoDoorOnePin "Accommodates 1-4 digit codes. All unused digits shall be set to 0xF.  Valid code digits use BCD Encoding.  Example 0x1543 = Code 15432";
CM_ BO_ 522 "Odometer signals.";
CM_ SG_ 522 BackendTripMeter "FMS Trip Meter";
CM_ BO_ 1027 "Tethered Controller Software Version";
CM_ BO_ 1650 "Battery Statistics to CGM / Backend.";
CM_ SG_ 1650 CellTmprMax "The highest temperature level reported by any cell in the High Voltage Energy Storage System (or Pack 1 in systems with only one pack).
Previously named HVESSD3_Highest_Cell_Temp";
CM_ SG_ 1650 MsgCrc "mVehBattStat2 Message Checksum (E2E data ID: 0xA8)";
CM_ SG_ 1650 MvVoltBus "The voltage level of the high voltage bus, as measured by the High Voltage Energy Storage System (or Pack 1 in systems with only one pack) on the bus side (not the battery side) of its contactors.
Previously named HVESSD6_Bus_Voltage";
CM_ SG_ 1650 MvCurrBatt "The current in or out of the High Voltage Energy Storage 1 pack (or system).  This parameter should be synchronized with SPN 5919 (HVES1 Voltage Level) such that a realized power value can be calculated.  
Previously named HVESSD1_Current.";
CM_ BO_ 1649 "Battery Statistics to CGM / Backend.";
CM_ SG_ 1649 CellTmprMin "The lowest temperature level reported by any cell in the High Voltage Energy Storage System (or Pack 1 in systems with only one pack).
Previously named HVESSD3_Lowest_Cell_Temp.";
CM_ SG_ 1649 MsgCrc "mVehBattStat Message Checksum (E2E data ID: 0xA7)";
CM_ SG_ 1649 BattSocFast "Indicates the High Voltage Energy Storage System (or Pack 1 in systems with only one pack) state of charge.
Previously named HVESSD2_State_Of_Charge
";
CM_ BO_ 1648 "Last 8 chars of VIN or Serial Number";
CM_ SG_ 1648 VIN_Char17 "VIN Character 17 - Sequential Build Number";
CM_ SG_ 1648 VIN_Char16 "VIN Character 16 - Sequential Build Number";
CM_ SG_ 1648 VIN_Char15 "VIN Character 15 - Sequential Build Number";
CM_ SG_ 1648 VIN_Char14 "VIN Character 14 - Sequential Build Number";
CM_ SG_ 1648 VIN_Char13 "VIN Character 13 - Sequential Build Number";
CM_ SG_ 1648 VIN_Char12 "VIN Character 12 - Sequential Build Number";
CM_ SG_ 1648 VIN_Char11 "VIN Character 11 - Plant Code";
CM_ SG_ 1648 VIN_Char10 "VIN Character 10 -  Model Year";
CM_ BO_ 1024 "Left Joystick from Tethered Controller";
CM_ SG_ 1024 MsgCrc "mTCLeftJoyStat Message Checksum (E2E data ID: 0x60)";
CM_ SG_ 1024 Btn_Dwn "Tethered Controller Button Down.";
CM_ SG_ 1024 Btn_Left "Tethered Controller Button Left.";
CM_ SG_ 1024 Btn_Right "Tethered Controller Button Right.";
CM_ SG_ 1024 Btn_Up "Tethered Controller Button Up.";
CM_ BO_ 1026 "Right Joystick from Tethered Controller";
CM_ SG_ 1026 MsgCrc "mTCRightJoyStat Message Checksum (E2E data ID: 0x61)";
CM_ SG_ 1026 Btn_4 "Tethered Controller Button 4.";
CM_ SG_ 1026 Btn_3 "Tethered Controller Button 3.";
CM_ SG_ 1026 Btn_2 "Tethered Controller Button 2.";
CM_ SG_ 1026 Btn_1 "Tethered Controller Button 1.";
CM_ BO_ 289 "Vehicle Control Request from TeleOperations.";
CM_ SG_ 289 MsgCrc "mVehCtrlTORq Message Checksum (E2E data ID: 0x42)";
CM_ BO_ 288 "TeleOperations Status";
CM_ SG_ 288 TO_dlg_resp_id "0 = TeleOps has not responded yet.
1 = Go - Continue AD Control
2 = No Go.  TeleOps has Acknowledged and will take remote control based on priority.";
CM_ SG_ 288 TO_dlg_resp_code "Response from TO Operator to Allow / Deny AD Control Request.";
CM_ SG_ 288 VehDirCmd "Gear direction request from TO.";
CM_ SG_ 288 MsgCrc "mTOStat Message Checksum (E2E data ID: 0x41)";
CM_ BO_ 1952 "The DLC of the diagnosis message in the matrix is only used to generate the DBC file, and the DLC length used in the actual development of the ECU shall meet the technical requirements of the UDS.";
CM_ BO_ 1160 "CGM Heartbeat for time synchronization.";
CM_ SG_ 1368 adcu_ros_bridge_fault "Flag indicating ROS Bridge Fault";
CM_ SG_ 1368 adcu_grpc_bridge_fault "Flag indicating GRPC Bridge Fault";
CM_ BO_ 528 "CGM Heartbeat for time synchronization.";
CM_ BO_ 1367 "Software version of CGM (A Core)";
CM_ SG_ 1367 SwStat "Release status of software.";
CM_ SG_ 1367 SwRev "Revision of Software version.";
CM_ SG_ 1367 SwMin "Minor version of Software.";
CM_ SG_ 1367 SwMaj "Major version of Software.";
CM_ BO_ 772 "Software versions of vehicle components";
CM_ SG_ 772 EPB_SwRev "Revision of Software version.";
CM_ SG_ 772 Ebcm2L_SwVerStat "Version Status";
CM_ SG_ 772 Ebcm2L_SwVerRev "Bugfix Version number";
CM_ SG_ 772 AVAS_SwMin "Minor Software Version";
CM_ SG_ 772 AVAS_SwMaj "Major Software Version";
CM_ SG_ 772 Ebcm2L_SwVerMin "Minor Software Version";
CM_ SG_ 772 Ebcm1U_SwVerMin "Minor Software Version";
CM_ SG_ 772 Ebcm2L_SwVerMaj "Major Software Version";
CM_ SG_ 772 Ebcm1U_SwVerMaj "Major Software Version";
CM_ SG_ 772 Ebcm1U_SwVerStat "Version Status";
CM_ SG_ 772 Ebcm1U_SwVerRev "Bugfix Version number";
CM_ BO_ 290 "Vehicle Feedback to TeleOperations.";
CM_ SG_ 290 MsgCrc "mVehFdbkTO Message Checksum (E2E data ID: 0x43)";
CM_ SG_ 290 EstopDetected "Indication that Estop has been detected.";
CM_ BO_ 1555 "ADCU Status";
CM_ SG_ 1555 AdcuStatus "Overall status of ADCU.";
CM_ SG_ 1555 AdcuShtdwnRdy "Flag indicating that ADCU has performed shutdown routine and is ready for power to be removed.";
CM_ SG_ 1555 AdcuEstopRq "Flag indicating Emergency Stop condition (not AEB).";
CM_ SG_ 1555 MsgCrc "mAdcuStat Message Checksum (E2E data ID: 0xA6)";
CM_ SG_ 1555 MsgCntr "Check the MessageCounter consistency at least on every message reception";
CM_ SG_ 1555 TO_Assistance_Rq "ADCU is requesting assistance from TO operator.  Since signal is passed through VCU, generally it will reflect the value as received from ADCU.  If VCU has lost communication with ADU, VCU may directly request Remote Control to TO.";
CM_ SG_ 1555 AD_Ready "Flag indicating that AD is ready to take control of LMDD.";
CM_ SG_ 1555 AD_Mission_Cmplt "Flag indicating AD Mission Completion status.";
CM_ BO_ 1554 "Previously named 'ExtLightsCmd'";
CM_ SG_ 1554 LightTurnCmdR "Right Turn Signal Command from TO.";
CM_ SG_ 1554 LightTurnCmdL "Left Turn Signal request from TO.";
CM_ SG_ 1554 LightHighCmd "High Beam Light Command from TO.";
CM_ SG_ 1554 LightHazardCmd "Hazard Light Command from TO.";
CM_ SG_ 1554 MsgCrc "mExtLightsTORq Message Checksum (E2E data ID: 0xAA)";
CM_ BO_ 1793 "ADCU Software version.";
CM_ SG_ 1793 SwStat "Release status of software.";
CM_ SG_ 1793 SwRev "Revision of Software version.";
CM_ SG_ 1793 SwMin "Minor version of Software.";
CM_ SG_ 1793 SwMaj "Major version of Software.";
CM_ BO_ 516 "VCU Faults Reporting";
CM_ SG_ 516 Flt_LocFcmCan "Loss of Com Fault on FCM on CAN";
CM_ BO_ 514 "Vehicle Level State Data.";
CM_ SG_ 514 Invld_GearRq "Invalid Gear Transition is being requested by Controlling Source (AD / TO / LOS)";
CM_ SG_ 514 EstopDetected "Indication that Estop has been detected.";
CM_ SG_ 514 ArbVehSpdValid "Validity for Arbitrated Vehicle Speed.";
CM_ SG_ 514 ArbVehSpd "VCU Arbitrated Vehicle Speed";
CM_ SG_ 514 MsgCrc "mVehState Message Checksum (E2E data ID: 0x50)";
CM_ SG_ 514 CrashSns "Crash condition has been sensed.";
CM_ BO_ 512 "Status of Exterior Lights";
CM_ SG_ 512 LightTurnRearRStat "Actual Status of Right Rear Turn Lamp.";
CM_ SG_ 512 LightTurnRearLStat "Actual Status of Left Rear Turn Lamp.";
CM_ SG_ 512 LightTurnFrontRStat "Actual Status of Right Front Turn Lamp.";
CM_ SG_ 512 LightTurnFrontLStat "Actual Status of Left Front Turn Lamp.";
CM_ SG_ 512 LightHighStat "Actual High Beam Lamp Status.";
CM_ SG_ 512 LightLow_TailStat "Actual Status of Tail Lamp, Low Beam, and License Lamp.";
CM_ SG_ 512 LightDRLStat "Actual DRL Lamp Status.";
CM_ SG_ 512 LightStopStat "Actual Status of Stop Lamp.";
CM_ SG_ 512 LightChmslStat "Actual CHMSL Lamp Status.";
CM_ SG_ 512 LightRevStat "Actual Status of Reverse Lamp.";
CM_ SG_ 512 HornStat "Actual Horn Status.";
CM_ BO_ 2634005196 "LMDD Vehicle ID";
CM_ BO_ 2634009804 "VCU Software Version";
BA_DEF_ SG_  "SigType" ENUM  "Default","Range","RangeSigned","ASCII","Discrete","Control","ReferencePGN","DTC","StringDelimiter","StringLength","StringLengthControl","MessageCounter","MessageChecksum";
BA_DEF_ SG_  "Gateway_ID" INT 0 0;
BA_DEF_ SG_  "GenSigEVName" STRING ;
BA_DEF_ SG_  "GenSigILSupport" ENUM  "No","Yes";
BA_DEF_ SG_  "GenSigSendType" ENUM  "Cyclic","OnWrite","OnWriteWithRepetition","OnChange","OnChangeWithRepetition","IfActive","IfActiveWithRepetition","NoSigSendType";
BA_DEF_ SG_  "GenSigStartValue" INT 0 2147483647;
BA_DEF_ BO_  "GenMsgCycleTimeFast" INT 0 3600000;
BA_DEF_ BO_  "GenMsgILSupport" ENUM  "No","Yes";
BA_DEF_ BO_  "GenMsgRequestable" INT 0 1;
BA_DEF_ BO_  "GenMsgStartDelayTime" INT 0 100000;
BA_DEF_ BO_  "GenMsgSendType" ENUM  "Cyclic","NotUsed","IfActive","On Request","NotUsed","NotUsed","NotUsed","NotUsed","noMsgSendType";
BA_DEF_ BO_  "GenMsgCycleTime" INT 0 3600000;
BA_DEF_  "DBName" STRING ;
BA_DEF_  "BusType" STRING ;
BA_DEF_  "Baudrate" INT 0 0;
BA_DEF_DEF_  "SigType" "Default";
BA_DEF_DEF_  "Gateway_ID" 0;
BA_DEF_DEF_  "GenSigEVName" "Env@Nodename_@Signame";
BA_DEF_DEF_  "GenSigILSupport" "Yes";
BA_DEF_DEF_  "GenSigSendType" "NoSigSendType";
BA_DEF_DEF_  "GenSigStartValue" 0;
BA_DEF_DEF_  "GenMsgCycleTimeFast" 0;
BA_DEF_DEF_  "GenMsgILSupport" "Yes";
BA_DEF_DEF_  "GenMsgRequestable" 1;
BA_DEF_DEF_  "GenMsgStartDelayTime" 0;
BA_DEF_DEF_  "GenMsgSendType" "noMsgSendType";
BA_DEF_DEF_  "GenMsgCycleTime" 0;
BA_DEF_DEF_  "DBName" "";
BA_DEF_DEF_  "BusType" "CAN";
BA_DEF_DEF_  "Baudrate" 500000;
BA_ "DBName" "CAN_TC";
BA_ "GenMsgCycleTimeFast" BO_ 1569 1000;
BA_ "GenMsgSendType" BO_ 1569 0;
BA_ "GenMsgCycleTime" BO_ 1569 1000;
BA_ "GenMsgCycleTimeFast" BO_ 1568 1000;
BA_ "GenMsgSendType" BO_ 1568 0;
BA_ "GenMsgCycleTime" BO_ 1568 1000;
BA_ "GenMsgSendType" BO_ 1960 3;
BA_ "GenMsgCycleTimeFast" BO_ 771 100;
BA_ "GenMsgSendType" BO_ 771 0;
BA_ "GenMsgCycleTime" BO_ 771 100;
BA_ "GenMsgCycleTimeFast" BO_ 521 50;
BA_ "GenMsgSendType" BO_ 521 0;
BA_ "GenMsgCycleTime" BO_ 521 50;
BA_ "GenMsgCycleTimeFast" BO_ 1366 100;
BA_ "GenMsgSendType" BO_ 1366 0;
BA_ "GenMsgCycleTime" BO_ 1366 100;
BA_ "GenMsgCycleTimeFast" BO_ 1365 100;
BA_ "GenMsgSendType" BO_ 1365 0;
BA_ "GenMsgCycleTime" BO_ 1365 100;
BA_ "GenMsgCycleTimeFast" BO_ 1364 500;
BA_ "GenMsgSendType" BO_ 1364 0;
BA_ "GenMsgCycleTime" BO_ 1364 500;
BA_ "GenMsgCycleTimeFast" BO_ 1363 500;
BA_ "GenMsgSendType" BO_ 1363 0;
BA_ "GenMsgCycleTime" BO_ 1363 500;
BA_ "GenMsgCycleTimeFast" BO_ 522 100;
BA_ "GenMsgSendType" BO_ 522 0;
BA_ "GenMsgCycleTime" BO_ 522 100;
BA_ "GenMsgCycleTimeFast" BO_ 1027 1000;
BA_ "GenMsgSendType" BO_ 1027 0;
BA_ "GenMsgCycleTime" BO_ 1027 1000;
BA_ "GenMsgCycleTimeFast" BO_ 1650 100;
BA_ "GenMsgSendType" BO_ 1650 0;
BA_ "GenMsgCycleTime" BO_ 1650 100;
BA_ "GenMsgCycleTimeFast" BO_ 1649 100;
BA_ "GenMsgSendType" BO_ 1649 0;
BA_ "GenMsgCycleTime" BO_ 1649 100;
BA_ "GenMsgCycleTimeFast" BO_ 1648 10000;
BA_ "GenMsgSendType" BO_ 1648 0;
BA_ "GenMsgCycleTime" BO_ 1648 10000;
BA_ "GenMsgCycleTimeFast" BO_ 1024 100;
BA_ "GenMsgSendType" BO_ 1024 0;
BA_ "GenMsgCycleTime" BO_ 1024 100;
BA_ "GenMsgCycleTimeFast" BO_ 1026 100;
BA_ "GenMsgSendType" BO_ 1026 0;
BA_ "GenMsgCycleTime" BO_ 1026 100;
BA_ "GenMsgSendType" BO_ 289 0;
BA_ "GenMsgCycleTime" BO_ 289 20;
BA_ "GenMsgCycleTimeFast" BO_ 288 500;
BA_ "GenMsgSendType" BO_ 288 0;
BA_ "GenMsgCycleTime" BO_ 288 500;
BA_ "GenMsgSendType" BO_ 1920 3;
BA_ "GenMsgCycleTimeFast" BO_ 1160 100;
BA_ "GenMsgSendType" BO_ 1160 0;
BA_ "GenMsgCycleTime" BO_ 1160 100;
BA_ "GenMsgCycleTimeFast" BO_ 1368 500;
BA_ "GenMsgSendType" BO_ 1368 0;
BA_ "GenMsgCycleTime" BO_ 1368 500;
BA_ "GenMsgCycleTimeFast" BO_ 528 500;
BA_ "GenMsgSendType" BO_ 528 0;
BA_ "GenMsgCycleTime" BO_ 528 500;
BA_ "GenMsgCycleTimeFast" BO_ 1367 500;
BA_ "GenMsgSendType" BO_ 1367 0;
BA_ "GenMsgCycleTime" BO_ 1367 500;
BA_ "GenMsgCycleTimeFast" BO_ 772 10000;
BA_ "GenMsgSendType" BO_ 772 0;
BA_ "GenMsgCycleTime" BO_ 772 10000;
BA_ "GenMsgCycleTimeFast" BO_ 290 20;
BA_ "GenMsgSendType" BO_ 290 0;
BA_ "GenMsgCycleTime" BO_ 290 20;
BA_ "GenMsgSendType" BO_ 1555 0;
BA_ "GenMsgCycleTime" BO_ 1555 20;
BA_ "GenMsgCycleTimeFast" BO_ 1554 500;
BA_ "GenMsgSendType" BO_ 1554 0;
BA_ "GenMsgCycleTime" BO_ 1554 500;
BA_ "GenMsgSendType" BO_ 1793 0;
BA_ "GenMsgCycleTime" BO_ 1793 10000;
BA_ "GenMsgSendType" BO_ 516 0;
BA_ "GenMsgCycleTime" BO_ 516 100;
BA_ "GenMsgSendType" BO_ 514 0;
BA_ "GenMsgCycleTime" BO_ 514 50;
BA_ "GenMsgSendType" BO_ 512 0;
BA_ "GenMsgCycleTime" BO_ 512 20;
BA_ "GenMsgSendType" BO_ 2634005196 0;
BA_ "GenMsgCycleTime" BO_ 2634005196 10000;
BA_ "GenMsgSendType" BO_ 2634009804 0;
BA_ "GenMsgCycleTime" BO_ 2634009804 10000;
BA_ "Gateway_ID" SG_ 1650 CellTmprMax 2511;
BA_ "Gateway_ID" SG_ 1650 MvVoltBus 2521;
BA_ "Gateway_ID" SG_ 1650 MvCurrBatt 2502;
BA_ "Gateway_ID" SG_ 1649 CellTmprMin 2512;
BA_ "Gateway_ID" SG_ 1649 BattSocFast 2508;
BA_ "Gateway_ID" SG_ 289 MsgCrc 2418;
BA_ "Gateway_ID" SG_ 289 TO_EstopRq 2176;
BA_ "Gateway_ID" SG_ 289 TO_Steer_Cmd 2321;
BA_ "Gateway_ID" SG_ 289 TO_Accel_Cmd 2320;
BA_ "Gateway_ID" SG_ 289 MsgCntr 2411;
BA_ "Gateway_ID" SG_ 288 TO_cmd_veh_mode 2175;
BA_ "Gateway_ID" SG_ 288 TO_ConnectionStat 2173;
BA_ "Gateway_ID" SG_ 288 TO_dlg_resp_id 2171;
BA_ "Gateway_ID" SG_ 288 TO_dlg_resp_code 2168;
BA_ "GenSigStartValue" SG_ 288 TO_dlg_resp_code 3;
BA_ "Gateway_ID" SG_ 288 VehDirCmd 2181;
BA_ "Gateway_ID" SG_ 288 MsgCrc 2417;
BA_ "Gateway_ID" SG_ 288 MsgCntr 2412;
BA_ "Gateway_ID" SG_ 1555 AdcuStatus 1381;
BA_ "Gateway_ID" SG_ 1555 AdcuShtdwnRdy 1380;
BA_ "Gateway_ID" SG_ 1555 AdcuEstopRq 1379;
BA_ "Gateway_ID" SG_ 1555 MsgCrc 1378;
BA_ "Gateway_ID" SG_ 1555 MsgCntr 1377;
BA_ "Gateway_ID" SG_ 1555 TO_Assistance_Rq 2172;
BA_ "Gateway_ID" SG_ 1555 AD_Ready 2170;
BA_ "Gateway_ID" SG_ 1555 AD_Mission_Cmplt 2169;
BA_ "Gateway_ID" SG_ 1793 SwStat 1348;
BA_ "Gateway_ID" SG_ 1793 SwRev 1347;
BA_ "Gateway_ID" SG_ 1793 SwMin 1346;
BA_ "Gateway_ID" SG_ 1793 SwMaj 1345;
VAL_ 1569 PTT_SteerSysChkSts 3 "NACK, Request Rejected - Fault" 2 "ACK, Test Removed" 1 "ACK, Test Scheduled" 0 "Test Not Scheduled" ;
VAL_ 1569 PTT_ExtLightChkSts 3 "NACK, Request Rejected - Fault" 2 "ACK, Test Removed" 1 "ACK, Test Scheduled" 0 "Test Not Scheduled" ;
VAL_ 1569 PTT_EpbChkSts 3 "NACK, Request Rejected - Fault" 2 "ACK, Test Removed" 1 "ACK, Test Scheduled" 0 "Test Not Scheduled" ;
VAL_ 1569 PTT_BrkChkSts 3 "NACK, Request Rejected - Fault" 2 "ACK, Test Removed" 1 "ACK, Test Scheduled" 0 "Test Not Scheduled" ;
VAL_ 1569 PTT_AudioAlertsSts 3 "NACK, Request Rejected - Fault" 2 "ACK, Test Removed" 1 "ACK, Test Scheduled" 0 "Test Not Scheduled" ;
VAL_ 1569 PTT_48VSysChkSts 3 "NACK, Request Rejected - Fault" 2 "ACK, Test Removed" 1 "ACK, Test Scheduled" 0 "Test Not Scheduled" ;
VAL_ 1568 PTT_SteerSysChk 2 "Remove Scheduled Test" 1 "Schedule Test" 0 "Idle / No Request" ;
VAL_ 1568 PTT_ExtLightChk 2 "Remove Scheduled Test" 1 "Schedule Test" 0 "Idle / No Request" ;
VAL_ 1568 PTT_EpbChk 2 "Remove Scheduled Test" 1 "Schedule Test" 0 "Idle / No Request" ;
VAL_ 1568 PTT_BrkChk 2 "Remove Scheduled Test" 1 "Schedule Test" 0 "Idle / No Request" ;
VAL_ 1568 PTT_AudioAlertsChk 2 "Remove Scheduled Test" 1 "Schedule Test" 0 "Idle / No Request" ;
VAL_ 1568 PTT_48VSysChk 2 "Remove Scheduled Test" 1 "Schedule Test" 0 "Idle / No Request" ;
VAL_ 771 SteerSysChk 6 "Disabled" 4 "Not Run - 12V Flt" 3 "Not Run - Steer Flt" 2 "Fail" 1 "OK" 0 "SNA" ;
VAL_ 771 PreTripStat 3 "DisabledAll" 2 "EnabledScheduled" 1 "EnabledMdtry" 0 "SNA" ;
VAL_ 771 PreTripRslt 10 "Fail Mdtry & Fail Schd" 6 "Fail Mdtry & Pass Schd" 9 "Pass Mdtry &  Fail Schd" 8 "Failed Scheduled" 5 "Pass Mdtry & Pass Schd" 4 "Passed Scheduled" 2 "Failed Mandatory" 1 "Passed Mandatory" 0 "SNA / Not Run" ;
VAL_ 771 MvSysChk 15 "Disabled" 10 "Batt1 Fail, Batt2 Fail" 9 "Batt1 Pass, Batt2 Fail" 8 "Batt1 Not Run, Batt2 Fail" 6 "Batt1 Fail, Batt2 Pass" 5 "Batt1 Pass, Batt2 Pass" 4 "Batt1 Not Run, Batt2 Pass" 2 "Batt1 Fail, Batt2 Not Run" 1 "Batt1 Pass, Batt2 Not Run" 0 "SNA / Not Run" ;
VAL_ 771 LvSysChk 2 "Fail" 1 "OK" 0 "SNA / Not Run" ;
VAL_ 771 LvBattChk 5 "Not Run - Charger" 4 "Fail Dead" 3 "Fail Warn" 2 "Low" 1 "OK" 0 "SNA / Not Run" ;
VAL_ 771 ExtLghtChk 28 "High, Turn, + Brake Fail" 24 "Brake + Turn Fail" 128 "Disabled " 32 "NotRun-12VFlt" 30 "Low, High, Turn, + Brake Fail" 26 "Low, Turn, + Brake Fail" 22 "Low, High, + Brake Fail" 12 "Highbeam + Turn Fail" 20 "Highbeam + Brake Fail" 18 "Lowbeam + Brake Fail" 16 "Brake Lght_Fail" 14 "Low, High, + Turn Fail" 10 "Lowbeam + Turn Fail" 8 "TurnSgnl_Fail" 6 "Lowbeam + Highbeam Fail" 4 "Highbeam Fail" 2 "Low Beam / Tail / Lic Fail" 1 "OK" 0 "SNA / Not Run" ;
VAL_ 771 EpbChk 15 "Disabled" 7 "Not Run - SpdSnsFlt" 6 "Not Run - EpbDisengFlt," 5 "Not Run - 12VFlt" 4 "Not Run - BrkFlt" 3 "Not Run - Grade" 2 "Fail" 1 "OK" 0 "SNA / Not Run" ;
VAL_ 771 BrkChk 15 "Disabled" 7 "Not Run - SpdSnsFlt" 6 "Not Run - EpbDisengFlt," 5 "Not Run - 12VFlt" 4 "Not Run - BrkFlt" 3 "Not Run - Grade" 2 "Fail" 1 "OK" 0 "SNA / Not Run" ;
VAL_ 771 AudioAlrtChk 15 "Disabled" 7 "Not Run - Electrical Flt" 6 "Not Run - 12V Flt" 5 "Not Run - High Noise" 4 "Audio Alert + Horn Fail" 3 "Horn Fail" 2 "Audio Alert Fail" 1 "OK" 0 "SNA / Not Run" ;
VAL_ 521 TargetVehSpd_mps 2047 "SNA" 2046 "Fault" ;
VAL_ 521 AebSrc 15 "FCM + LIDAR + Thermal + LRR" 14 "Thermal + LIDAR + LRR" 13 "FCM + Thermal + LRR" 12 "Thermal + LRR" 11 "FCM + LIDAR + LRR" 10 "LIDAR + LRR" 9 "FCM + LRR" 8 "LRR" 7 "FCM + LIDAR + Thermal" 6 "LIDAR + Thermal" 5 "FCM + Thermal" 4 "Thermal" 3 "FCM + LIDAR" 2 "LIDAR" 1 "FCM" 0 "No AEB Event" ;
VAL_ 521 Aeb_Active 1 "AEB event is Active" 0 "No AEB event active" ;
VAL_ 521 ArbVehSpd_mps_Valid 1 "Valid" 0 "Invalid" ;
VAL_ 521 ArbVehSpd_mps 2047 "SNA" 2046 "Fault" ;
VAL_ 1366 CargoHeatPad2Stat 2 "Fault" 1 "ON" 0 "OFF" ;
VAL_ 1366 CargoDoor2Stat 2 "Open" 1 "Moving" 0 "Closed" ;
VAL_ 1366 DeliveryStatusCargo2 2 "Ready To Deliver" 1 "Delivery In Progress" 0 "Idle" 4 "Delivery Timed Out" 3 "Delivery Successful" ;
VAL_ 1365 DeliveryStatusCargo1 2 "Ready To Deliver" 1 "Delivery In Progress" 0 "Idle" 4 "Delivery Timed Out" 3 "Delivery Successful" ;
VAL_ 1365 CargoHeatPad1Stat 2 "Fault" 1 "ON" 0 "OFF" ;
VAL_ 1365 CargoDoor1Stat 2 "Open" 1 "Moving" 0 "Closed" ;
VAL_ 1365 LightCargoStat 8 "Open Load" 4 "Short To Ground" 2 "Short To Battery" 1 "On" 0 "Off" ;
VAL_ 1364 AllowDeliveryMode 1 "Arrived / Cargo Unlocked" 0 "Enroute / Cargo Locked" ;
VAL_ 1364 jobType 3 "Relocation" 2 "Pickup" 1 "Delivery" 0 "None" ;
VAL_ 1364 BETripMeterStart 1 "Start" 0 "Normal" ;
VAL_ 1364 BETripMeterReset 1 "Reset Trip Meter" 0 "Normal" ;
VAL_ 1364 tripIsActive 1 "Active" 0 "Not Active" ;
VAL_ 1364 Bay2HtrRemoteCmd 1 "ON" 0 "OFF" ;
VAL_ 1364 Bay2DoorRemoteCmd 2 "No Remote Command" 1 "Close" 0 "Open" ;
VAL_ 1364 Bay1HtrRemoteCmd 1 "ON" 0 "OFF" ;
VAL_ 1364 Bay1DoorRemoteCmd 2 "No Remote Command" 1 "Close" 0 "Open" ;
VAL_ 522 BackendTripMeter 65535 "SNA" 65534 "Fault" ;
VAL_ 522 VcuTripMeter 65535 "SNA" 65534 "Fault" ;
VAL_ 522 VehOdo 16777215 "SNA" 16777214 "Fault" ;
VAL_ 1648 VIN_Char17 90 "Z" 89 "Y" 88 "X" 87 "W" 86 "V" 85 "U" 84 "T" 83 "S" 82 "R" 80 "P" 78 "N" 77 "M" 76 "L" 75 "K" 74 "J" 72 "H" 71 "G" 70 "F" 69 "E" 68 "D" 67 "C" 66 "B" 65 "A" 57 "9" 56 "8" 55 "7" 54 "6" 53 "5" 52 "4" 51 "3" 50 "2" 49 "1" 48 "0" ;
VAL_ 1648 VIN_Char16 90 "Z" 89 "Y" 88 "X" 87 "W" 86 "V" 85 "U" 84 "T" 83 "S" 82 "R" 80 "P" 78 "N" 77 "M" 76 "L" 75 "K" 74 "J" 72 "H" 71 "G" 70 "F" 69 "E" 68 "D" 67 "C" 66 "B" 65 "A" 57 "9" 56 "8" 55 "7" 54 "6" 53 "5" 52 "4" 51 "3" 50 "2" 49 "1" 48 "0" ;
VAL_ 1648 VIN_Char15 90 "Z" 89 "Y" 88 "X" 87 "W" 86 "V" 85 "U" 84 "T" 83 "S" 82 "R" 80 "P" 78 "N" 77 "M" 76 "L" 75 "K" 74 "J" 72 "H" 71 "G" 70 "F" 69 "E" 68 "D" 67 "C" 66 "B" 65 "A" 57 "9" 56 "8" 55 "7" 54 "6" 53 "5" 52 "4" 51 "3" 50 "2" 49 "1" 48 "0" ;
VAL_ 1648 VIN_Char14 90 "Z" 89 "Y" 88 "X" 87 "W" 86 "V" 85 "U" 84 "T" 83 "S" 82 "R" 80 "P" 78 "N" 77 "M" 76 "L" 75 "K" 74 "J" 72 "H" 71 "G" 70 "F" 69 "E" 68 "D" 67 "C" 66 "B" 65 "A" 57 "9" 56 "8" 55 "7" 54 "6" 53 "5" 52 "4" 51 "3" 50 "2" 49 "1" 48 "0" ;
VAL_ 1648 VIN_Char13 90 "Z" 89 "Y" 88 "X" 87 "W" 86 "V" 85 "U" 84 "T" 83 "S" 82 "R" 80 "P" 78 "N" 77 "M" 76 "L" 75 "K" 74 "J" 72 "H" 71 "G" 70 "F" 69 "E" 68 "D" 67 "C" 66 "B" 65 "A" 57 "9" 56 "8" 55 "7" 54 "6" 53 "5" 52 "4" 51 "3" 50 "2" 49 "1" 48 "0" ;
VAL_ 1648 VIN_Char12 90 "Z" 89 "Y" 88 "X" 87 "W" 86 "V" 85 "U" 84 "T" 83 "S" 82 "R" 80 "P" 78 "N" 77 "M" 76 "L" 75 "K" 74 "J" 72 "H" 71 "G" 70 "F" 69 "E" 68 "D" 67 "C" 66 "B" 65 "A" 57 "9" 56 "8" 55 "7" 54 "6" 53 "5" 52 "4" 51 "3" 50 "2" 49 "1" 48 "0" ;
VAL_ 1648 VIN_Char11 90 "Z" 89 "Y" 88 "X" 87 "W" 86 "V" 85 "U" 84 "T" 83 "S" 82 "R" 80 "P" 78 "N" 77 "M" 76 "L" 75 "K" 74 "J" 72 "H" 71 "G" 70 "F" 69 "E" 68 "D" 67 "C" 66 "B" 65 "A" 57 "9" 56 "8" 55 "7" 54 "6" 53 "5" 52 "4" 51 "3" 50 "2" 49 "1" 48 "0" ;
VAL_ 1648 VIN_Char10 90 "Z" 89 "Y" 88 "X" 87 "W" 86 "V" 85 "U" 84 "T" 83 "S" 82 "R" 80 "P" 78 "N" 77 "M" 76 "L" 75 "K" 74 "J" 72 "H" 71 "G" 70 "F" 69 "E" 68 "D" 67 "C" 66 "B" 65 "A" 57 "9" 56 "8" 55 "7" 54 "6" 53 "5" 52 "4" 51 "3" 50 "2" 49 "1" 48 "0" ;
VAL_ 1024 Left_Trigger 3 "SNA" 2 "Fault" 1 "Set" 0 "Not Set" ;
VAL_ 1024 MsgCntr 15 "Fault" ;
VAL_ 1024 Btn_Dwn 3 "SNA" 2 "Fault" 1 "Set" 0 "Not Set" ;
VAL_ 1024 Btn_Left 3 "SNA" 2 "Fault" 1 "Set" 0 "Not Set" ;
VAL_ 1024 Btn_Right 3 "SNA" 2 "Fault" 1 "Set" 0 "Not Set" ;
VAL_ 1024 Btn_Up 3 "SNA" 2 "Fault" 1 "Set" 0 "Not Set" ;
VAL_ 1024 LeftX_Neg 3 "SNA" 2 "Fault" 1 "Set" 0 "Not Set" ;
VAL_ 1024 LeftX_Ntrl 3 "SNA" 2 "Fault" 1 "Set" 0 "Not Set" ;
VAL_ 1024 LeftX_Pos 3 "SNA" 2 "Fault" 1 "Set" 0 "Not Set" ;
VAL_ 1024 LeftY_Neg 3 "SNA" 2 "Fault" 1 "Set" 0 "Not Set" ;
VAL_ 1024 LeftY_Ntrl 3 "SNA" 2 "Fault" 1 "Set" 0 "Not Set" ;
VAL_ 1024 LeftY_Pos 3 "SNA" 2 "Fault" 1 "Set" 0 "Not Set" ;
VAL_ 1026 MsgCntr 15 "Fault" ;
VAL_ 1026 Right_Trigger 3 "SNA" 2 "Fault" 1 "Set" 0 "Not Set" ;
VAL_ 1026 RightY_Pos 3 "SNA" 2 "Fault" 1 "Set" 0 "Not Set" ;
VAL_ 1026 RightY_Ntrl 3 "SNA" 2 "Fault" 1 "Set" 0 "Not Set" ;
VAL_ 1026 RightY_Neg 3 "SNA" 2 "Fault" 1 "Set" 0 "Not Set" ;
VAL_ 1026 RightX_Pos 3 "SNA" 2 "Fault" 1 "Set" 0 "Not Set" ;
VAL_ 1026 RightX_Ntrl 3 "SNA" 2 "Fault" 1 "Set" 0 "Not Set" ;
VAL_ 1026 RightX_Neg 3 "SNA" 2 "Fault" 1 "Set" 0 "Not Set" ;
VAL_ 1026 Btn_4 3 "SNA" 2 "Fault" 1 "Set" 0 "Not Set" ;
VAL_ 1026 Btn_3 3 "SNA" 2 "Fault" 1 "Set" 0 "Not Set" ;
VAL_ 1026 Btn_2 3 "SNA" 2 "Fault" 1 "Set" 0 "Not Set" ;
VAL_ 1026 Btn_1 3 "SNA" 2 "Fault" 1 "Set" 0 "Not Set" ;
VAL_ 289 TO_EstopRq 1 "True" 0 "False" ;
VAL_ 288 TO_cmd_veh_mode 4 "E-Stop" 3 "TeleOps" 2 "Monitor & Assist" 1 "<Unused - AD>" 0 "Unknown" ;
VAL_ 288 TO_ConnectionStat 2 "TeleOps in Session" 1 "Connected to Server" 0 "Disconnected" ;
VAL_ 288 TO_dlg_resp_id 2 "No" 1 "Yes" 0 "No Response / Waiting" ;
VAL_ 288 TO_dlg_resp_code 3 "Default" 1 "OperatorClick" 0 "Waiting" ;
VAL_ 288 VehDirCmd 3 "Drive" 2 "Invalid" 1 "Reverse" 0 "Park" ;
VAL_ 1368 vcu_connection_fault 1 "Fault" 0 "No Fault" ;
VAL_ 1368 to_connection_fault 1 "Fault" 0 "No Fault" ;
VAL_ 1368 modem_teleops_3_fault 1 "Fault" 0 "No Fault" ;
VAL_ 1368 modem_teleops_2_fault 1 "Fault" 0 "No Fault" ;
VAL_ 1368 modem_teleops_1_fault 1 "Fault" 0 "No Fault" ;
VAL_ 1368 modem_telematics_fault 1 "Fault" 0 "No Fault" ;
VAL_ 1368 gps_sensor_fault 1 "Fault" 0 "No Fault" ;
VAL_ 1368 fms_connection_fault 1 "Fault" 0 "No Fault" ;
VAL_ 1368 adcu_ros_bridge_fault 1 "Fault" 0 "No Fault" ;
VAL_ 1368 adcu_grpc_bridge_fault 1 "Fault" 0 "No Fault" ;
VAL_ 1367 SwStat 1 "Released" 0 "Development" ;
VAL_ 772 Ebcm2L_SwVerStat 1 "Released" 0 "Development" ;
VAL_ 772 Ebcm1U_SwVerStat 1 "Released" 0 "Development" ;
VAL_ 290 VCU_dlg_msg_rq 15 "reserved" 14 "reserved" 13 "reserved" 12 "reserved" 11 "reserved" 10 "reserved" 9 "reserved" 8 "reserved" 7 "End Trip <Park and Complete>" 6 "ControlRq AD" 5 "ControlRq VCU" 4 "Go / NoGo" 3 "AD Ready" 2 "Start Trip <Drive to Mapped Rd>" 1 "Session Request" 0 "No Popup" ;
VAL_ 290 EstopDetected 1 "ESTOP" 0 "OK" ;
VAL_ 1555 AdcuStatus 3 "Error" 2 "OK" 1 "Init" 0 "NA" ;
VAL_ 1555 AdcuShtdwnRdy 1 "True" 0 "False" ;
VAL_ 1555 AdcuEstopRq 1 "True" 0 "False" ;
VAL_ 1555 TO_Assistance_Rq 2 "Remote Control" 1 "Go / No Go" 0 "No Request" ;
VAL_ 1555 AD_Ready 1 "Ready" 0 "Not Ready" ;
VAL_ 1555 AD_Mission_Cmplt 1 "Complete" 0 "Not Complete" ;
VAL_ 1554 LightTurnCmdR 1 "True" 0 "False" ;
VAL_ 1554 LightTurnCmdL 1 "True" 0 "False" ;
VAL_ 1554 LightHighCmd 1 "True" 0 "False" ;
VAL_ 1554 HornCmd 1 "Horn" 0 "Off" ;
VAL_ 1554 LightHazardCmd 1 "True" 0 "False" ;
VAL_ 1793 SwStat 1 "Released" 0 "Development" ;
VAL_ 516 Flt_InvalidGearRq 1 "Fault" 0 "OK" ;
VAL_ 516 Flt_LocEpb 3 "Stored" 2 "Safety" 1 "Active" 0 "OK" ;
VAL_ 516 Flt_LocTo 3 "Stored" 2 "Safety" 1 "Active" 0 "OK" ;
VAL_ 516 Flt_LocBe 3 "Stored" 2 "Safety" 1 "Active" 0 "OK" ;
VAL_ 516 Flt_12vSys 1 "Fault" 0 "OK" ;
VAL_ 516 Flt_WriteEeprom 1 "Fault" 0 "OK" ;
VAL_ 516 Flt_ReadEeprom 1 "Fault" 0 "OK" ;
VAL_ 516 Flt_BrkSafeSys 1 "Fault" 0 "OK" ;
VAL_ 516 Flt_SafeCircuit 1 "Fault" 0 "OK" ;
VAL_ 516 Flt_MstrSwitch 1 "Fault" 0 "OK" ;
VAL_ 516 Flt_CntctrStat 3 "Unknown" 2 "Stuck Close" 1 "Stuck Open" 0 "OK" ;
VAL_ 516 Flt_BrkPrsr 1 "Fault" 0 "OK" ;
VAL_ 516 Flt_WhdEnbl 1 "Fault" 0 "OK" ;
VAL_ 516 Flt_SbwEnbl 1 "Fault" 0 "OK" ;
VAL_ 516 Flt_SafeSteer 3 "General" 2 "Response" 1 "Command" 0 "OK" ;
VAL_ 516 Flt_SafeProp 3 "General" 2 "Response" 1 "Command" 0 "OK" ;
VAL_ 516 Flt_SafeExtLight 3 "General" 2 "Response" 1 "Command" 0 "OK" ;
VAL_ 516 Flt_EpbSys 1 "Fault" 0 "OK" ;
VAL_ 516 Flt_DcdcEnbl 1 "Fault" 0 "OK" ;
VAL_ 516 Flt_48Volt 2 "Low" 1 "High" 0 "OK" ;
VAL_ 516 Flt_12Volt 2 "Low" 1 "High" 0 "OK" ;
VAL_ 516 Flt_LocWhd 3 "Stored" 2 "Safety" 1 "Active" 0 "OK" ;
VAL_ 516 Flt_LocTc 3 "Stored" 2 "Safety" 1 "Active" 0 "OK" ;
VAL_ 516 Flt_LocSbw 3 "Stored" 2 "Safety" 1 "Active" 0 "OK" ;
VAL_ 516 Flt_LocAVAS 3 "Stored" 2 "Safety" 1 "Active" 0 "OK" ;
VAL_ 516 Flt_LocVsc 3 "Stored" 2 "Safety" 1 "Active" 0 "OK" ;
VAL_ 516 Flt_LocEss 3 "Stored" 2 "Safety" 1 "Active" 0 "OK" ;
VAL_ 516 Flt_LocEbcm2 3 "Stored" 2 "Safety" 1 "Active" 0 "OK" ;
VAL_ 516 Flt_LocEbcm1 3 "Stored" 2 "Safety" 1 "Active" 0 "OK" ;
VAL_ 516 Flt_LocLrr 1 "Fault" 0 "OK" ;
VAL_ 516 Flt_KeypadLight 1 "Fault" 0 "OK" ;
VAL_ 516 Flt_KeypadC 1 "Fault" 0 "OK" ;
VAL_ 516 Flt_Keypad4 1 "Fault" 0 "OK" ;
VAL_ 516 Flt_LocFcmCan 1 "Fault" 0 "OK" ;
VAL_ 516 Flt_ImuRst 1 "Fault" 0 "OK" ;
VAL_ 516 Flt_ImuSns 1 "Fault" 0 "OK" ;
VAL_ 516 Flt_Bay2Pwr12v 1 "Fault" 0 "OK" ;
VAL_ 516 Flt_Bay2MtrPos 1 "Fault" 0 "OK" ;
VAL_ 516 Flt_Bay2Mtr 1 "Fault" 0 "OK" ;
VAL_ 516 Flt_Bay2BeltSns 1 "Fault" 0 "OK" ;
VAL_ 516 Flt_Bay1Pwr12v 1 "Fault" 0 "OK" ;
VAL_ 516 Flt_Bay1MtrPos 1 "Fault" 0 "OK" ;
VAL_ 516 Flt_Bay1Mtr 1 "Fault" 0 "OK" ;
VAL_ 516 Flt_Bay1BeltSns 1 "Fault" 0 "OK" ;
VAL_ 514 SBW_RtEndStopReached 1 "True" 0 "False" ;
VAL_ 514 SBW_LfEndStopReached 1 "True" 0 "False" ;
VAL_ 514 EstopDetected 1 "ESTOP" 0 "OK" ;
VAL_ 514 Tether_Connected 1 "Connected" 0 "Disconnected" ;
VAL_ 514 VehParkRq 1 "Park Request" 0 "No Request" ;
VAL_ 514 ArbVehSpdValid 1 "Valid" 0 "Invalid" ;
VAL_ 514 ArbVehSpd 2047 "SNA" 2046 "Fault" ;
VAL_ 514 GearRq 3 "Fwd" 1 "Rvrs" 0 "Park" 2 "Invalid" ;
VAL_ 514 GearChangeParkAllow 1 "Allowed" 0 "Not Allowed" ;
VAL_ 514 TO_Allowed 1 "Allowed" 0 "Not Allowed" ;
VAL_ 514 LOS_Allowed 1 "Allowed" 0 "Not Allowed" ;
VAL_ 514 AD_Allowed 1 "Allowed" 0 "Not Allowed" ;
VAL_ 514 GearChangeDrvRevAllow 1 "Allowed" 0 "Not Allowed" ;
VAL_ 514 GearAct 3 "Fwd" 2 "Ntrl" 1 "Rvrs" 0 "Park" ;
VAL_ 514 CrashSns 1 "True" 0 "False" ;
VAL_ 514 VcuEstopSns 1 "Estop" 0 "OK" ;
VAL_ 514 VehState 15 "Sleep" 13 "PreTripTest" 12 "Service" 11 "Crash" 10 "Shutdown" 9 "AEB" 8 "TO_Ctrl" 7 "Los_Ctrl" 6 "AD_Ctrl" 5 "Delivery_Mode" 4 "Vendor_Ops" 3 "Standby" 2 "System_Init" 1 "Wakeup" 0 "NA" ;
VAL_ 512 LightTurnRearRStat 8 "Open Load" 4 "Short To Ground" 2 "Short To Battery" 1 "On" 0 "Off" ;
VAL_ 512 LightTurnRearLStat 8 "Open Load" 4 "Short To Ground" 2 "Short To Battery" 1 "On" 0 "Off" ;
VAL_ 512 LightTurnFrontRStat 8 "Open Load" 4 "Short To Ground" 2 "Short To Battery" 1 "On" 0 "Off" ;
VAL_ 512 LightTurnFrontLStat 8 "Open Load" 4 "Short To Ground" 2 "Short To Battery" 1 "On" 0 "Off" ;
VAL_ 512 LightHighStat 8 "Open Load" 4 "Short To Ground" 2 "Short To Battery" 1 "On" 0 "Off" ;
VAL_ 512 LightLow_TailStat 8 "Open Load" 4 "Short To Ground" 2 "Short To Battery" 1 "On" 0 "Off" ;
VAL_ 512 LightDRLStat 8 "Open Load" 2 "Short To Battery" 1 "On" 0 "Off" 4 "Short To Ground" ;
VAL_ 512 LightStopStat 8 "Open Load" 4 "Short To Ground" 2 "Short To Battery" 1 "On" 0 "Off" ;
VAL_ 512 LightChmslStat 8 "Open Load" 3 "Short To Ground" 2 "Short To Battery" 1 "On" 0 "Off" ;
VAL_ 512 LightRevStat 8 "Open Load" 4 "Short To Ground" 2 "Short To Battery" 1 "On" 0 "Off" ;
VAL_ 512 HornStat 8 "Open Load" 4 "Short To Ground" 2 "Short To Battery" 1 "On" 0 "Off" ;
VAL_ 2634005196 VehId_Char8 32 " " 122 "z" 121 "y" 120 "x" 119 "w" 118 "v" 117 "u" 116 "t" 115 "s" 114 "r" 113 "q" 112 "p" 111 "o" 110 "n" 109 "m" 108 "l" 107 "k" 106 "j" 105 "i" 104 "h" 103 "g" 102 "f" 101 "e" 100 "d" 99 "c" 98 "b" 97 "a" 95 "_" 90 "Z" 89 "Y" 88 "X" 87 "W" 86 "V" 85 "U" 84 "T" 83 "S" 82 "R" 81 "Q" 80 "P" 79 "O" 78 "N" 77 "M" 76 "L" 75 "K" 74 "J" 73 "I" 72 "H" 71 "G" 70 "F" 69 "E" 68 "D" 67 "C" 66 "B" 65 "A" 57 "9" 56 "8" 55 "7" 54 "6" 53 "5" 52 "4" 51 "3" 50 "2" 49 "1" 48 "0" ;
VAL_ 2634005196 VehId_Char7 32 " " 122 "z" 121 "y" 120 "x" 119 "w" 118 "v" 117 "u" 116 "t" 115 "s" 114 "r" 113 "q" 112 "p" 111 "o" 110 "n" 109 "m" 108 "l" 107 "k" 106 "j" 105 "i" 104 "h" 103 "g" 102 "f" 101 "e" 100 "d" 99 "c" 98 "b" 97 "a" 95 "_" 90 "Z" 89 "Y" 88 "X" 87 "W" 86 "V" 85 "U" 84 "T" 83 "S" 82 "R" 81 "Q" 80 "P" 79 "O" 78 "N" 77 "M" 76 "L" 75 "K" 74 "J" 73 "I" 72 "H" 71 "G" 70 "F" 69 "E" 68 "D" 67 "C" 66 "B" 65 "A" 57 "9" 56 "8" 55 "7" 54 "6" 53 "5" 52 "4" 51 "3" 50 "2" 49 "1" 48 "0" ;
VAL_ 2634005196 VehId_Char6 32 " " 122 "z" 121 "y" 120 "x" 119 "w" 118 "v" 117 "u" 116 "t" 115 "s" 114 "r" 113 "q" 112 "p" 111 "o" 110 "n" 109 "m" 108 "l" 107 "k" 106 "j" 105 "i" 104 "h" 103 "g" 102 "f" 101 "e" 100 "d" 99 "c" 98 "b" 97 "a" 95 "_" 90 "Z" 89 "Y" 88 "X" 87 "W" 86 "V" 85 "U" 84 "T" 83 "S" 82 "R" 81 "Q" 80 "P" 79 "O" 78 "N" 77 "M" 76 "L" 75 "K" 74 "J" 73 "I" 72 "H" 71 "G" 70 "F" 69 "E" 68 "D" 67 "C" 66 "B" 65 "A" 57 "9" 56 "8" 55 "7" 54 "6" 53 "5" 52 "4" 51 "3" 50 "2" 49 "1" 48 "0" ;
VAL_ 2634005196 VehId_Char5 32 " " 122 "z" 121 "y" 120 "x" 119 "w" 118 "v" 117 "u" 116 "t" 115 "s" 114 "r" 113 "q" 112 "p" 111 "o" 110 "n" 109 "m" 108 "l" 107 "k" 106 "j" 105 "i" 104 "h" 103 "g" 102 "f" 101 "e" 100 "d" 99 "c" 98 "b" 97 "a" 95 "_" 90 "Z" 89 "Y" 88 "X" 87 "W" 86 "V" 85 "U" 84 "T" 83 "S" 82 "R" 81 "Q" 80 "P" 79 "O" 78 "N" 77 "M" 76 "L" 75 "K" 74 "J" 73 "I" 72 "H" 71 "G" 70 "F" 69 "E" 68 "D" 67 "C" 66 "B" 65 "A" 57 "9" 56 "8" 55 "7" 54 "6" 53 "5" 52 "4" 51 "3" 50 "2" 49 "1" 48 "0" ;
VAL_ 2634005196 VehId_Char4 32 " " 122 "z" 121 "y" 120 "x" 119 "w" 118 "v" 117 "u" 116 "t" 115 "s" 114 "r" 113 "q" 112 "p" 111 "o" 110 "n" 109 "m" 108 "l" 107 "k" 106 "j" 105 "i" 104 "h" 103 "g" 102 "f" 101 "e" 100 "d" 99 "c" 98 "b" 97 "a" 95 "_" 90 "Z" 89 "Y" 88 "X" 87 "W" 86 "V" 85 "U" 84 "T" 83 "S" 82 "R" 81 "Q" 80 "P" 79 "O" 78 "N" 77 "M" 76 "L" 75 "K" 74 "J" 73 "I" 72 "H" 71 "G" 70 "F" 69 "E" 68 "D" 67 "C" 66 "B" 65 "A" 57 "9" 56 "8" 55 "7" 54 "6" 53 "5" 52 "4" 51 "3" 50 "2" 49 "1" 48 "0" ;
VAL_ 2634005196 VehId_Char3 32 " " 122 "z" 121 "y" 120 "x" 119 "w" 118 "v" 117 "u" 116 "t" 115 "s" 114 "r" 113 "q" 112 "p" 111 "o" 110 "n" 109 "m" 108 "l" 107 "k" 106 "j" 105 "i" 104 "h" 103 "g" 102 "f" 101 "e" 100 "d" 99 "c" 98 "b" 97 "a" 95 "_" 90 "Z" 89 "Y" 88 "X" 87 "W" 86 "V" 85 "U" 84 "T" 83 "S" 82 "R" 81 "Q" 80 "P" 79 "O" 78 "N" 77 "M" 76 "L" 75 "K" 74 "J" 73 "I" 72 "H" 71 "G" 70 "F" 69 "E" 68 "D" 67 "C" 66 "B" 65 "A" 57 "9" 56 "8" 55 "7" 54 "6" 53 "5" 52 "4" 51 "3" 50 "2" 49 "1" 48 "0" ;
VAL_ 2634005196 VehId_Char2 32 " " 122 "z" 121 "y" 120 "x" 119 "w" 118 "v" 117 "u" 116 "t" 115 "s" 114 "r" 113 "q" 112 "p" 111 "o" 110 "n" 109 "m" 108 "l" 107 "k" 106 "j" 105 "i" 104 "h" 103 "g" 102 "f" 101 "e" 100 "d" 99 "c" 98 "b" 97 "a" 95 "_" 90 "Z" 89 "Y" 88 "X" 87 "W" 86 "V" 85 "U" 84 "T" 83 "S" 82 "R" 81 "Q" 80 "P" 79 "O" 78 "N" 77 "M" 76 "L" 75 "K" 74 "J" 73 "I" 72 "H" 71 "G" 70 "F" 69 "E" 68 "D" 67 "C" 66 "B" 65 "A" 57 "9" 56 "8" 55 "7" 54 "6" 53 "5" 52 "4" 51 "3" 50 "2" 49 "1" 48 "0" ;
VAL_ 2634005196 VehId_Char1 32 " " 122 "z" 121 "y" 120 "x" 119 "w" 118 "v" 117 "u" 116 "t" 115 "s" 114 "r" 113 "q" 112 "p" 111 "o" 110 "n" 109 "m" 108 "l" 107 "k" 106 "j" 105 "i" 104 "h" 103 "g" 102 "f" 101 "e" 100 "d" 99 "c" 98 "b" 97 "a" 95 "_" 90 "Z" 89 "Y" 88 "X" 87 "W" 86 "V" 85 "U" 84 "T" 83 "S" 82 "R" 81 "Q" 80 "P" 79 "O" 78 "N" 77 "M" 76 "L" 75 "K" 74 "J" 73 "I" 72 "H" 71 "G" 70 "F" 69 "E" 68 "D" 67 "C" 66 "B" 65 "A" 57 "9" 56 "8" 55 "7" 54 "6" 53 "5" 52 "4" 51 "3" 50 "2" 49 "1" 48 "0" ;
VAL_ 2634009804 SwStat 1 "Released" 0 "Development" ;
SIG_GROUP_ 1569 mFMS_PTT_Sched_FB 1 : PTT_SteerSysChkSts PTT_ExtLightChkSts PTT_EpbChkSts PTT_BrkChkSts PTT_AudioAlertsSts PTT_48VSysChkSts;
SIG_GROUP_ 1568 mFMS_PTT_Sched 1 : PTT_SteerSysChk PTT_ExtLightChk PTT_EpbChk PTT_BrkChk PTT_AudioAlertsChk PTT_48VSysChk;
SIG_GROUP_ 1842 mXCP_Vcu_Tx 1 : XCP_Byte_7 XCP_Byte_6 XCP_Byte_5 XCP_Byte_4 XCP_Byte_3 XCP_Byte_2 XCP_Byte_1 XCP_Byte_0;
SIG_GROUP_ 1841 mXCP_Vcu_Rx 1 : XCP_Byte_7 XCP_Byte_6 XCP_Byte_5 XCP_Byte_4 XCP_Byte_3 XCP_Byte_2 XCP_Byte_1 XCP_Byte_0;
SIG_GROUP_ 1840 mXCP_Broadcast 1 : XCP_Byte_5 XCP_Byte_2 XCP_Byte_0 XCP_Byte_1 XCP_Byte_3 XCP_Byte_4 XCP_Byte_6 XCP_Byte_7;
SIG_GROUP_ 1960 mDiagRs_VCU 1 : Diag_Byte_7 Diag_Byte_6 Diag_Byte_5 Diag_Byte_4 Diag_Byte_3 Diag_Byte_2 Diag_Byte_1 Diag_Byte_0;
SIG_GROUP_ 771 mPreTripStat 1 : SteerSysChk PreTripStat PreTripRslt MvSysChk MsgCrc MsgCntr LvSysChk LvBattChk ExtLghtChk EpbChk BrkChk AudioAlrtChk;
SIG_GROUP_ 521 mVehState3 1 : TargetVehSpd_mps ROI AebSrc Aeb_Active MsgCrc MsgCntr ArbVehSpd_mps_Valid ArbVehSpd_mps;
SIG_GROUP_ 1366 mVehCargoStat2 1 : MsgCntr CargoHeatPad2Stat CargoDoor2Stat tripCargoDoorTwoPinRcvd DeliveryStatusCargo2;
SIG_GROUP_ 1365 mVehCargoStat1 1 : MsgCntr DeliveryStatusCargo1 CargoHeatPad1Stat CargoDoor1Stat tripCargoDoorOnePinRcvd LightCargoStat;
SIG_GROUP_ 1364 mBECmd 1 : AllowDeliveryMode jobType BETripMeterStart BETripMeterReset tripIsActive Bay2HtrRemoteCmd Bay2DoorRemoteCmd Bay1HtrRemoteCmd Bay1DoorRemoteCmd MsgCrc MsgCntr;
SIG_GROUP_ 1363 mBECargoPIN 1 : tripCargoDoorTwoPin tripCargoDoorOnePin;
SIG_GROUP_ 522 mVehOdo 1 : VehOdo VcuTripMeter BackendTripMeter;
SIG_GROUP_ 1027 mTcSwVer 1 : HwMaj HwMin SwMaj SwMin;
SIG_GROUP_ 1650 mVehBattStat2 1 : MsgCntr MvCurrBatt MvVoltBus MsgCrc CellTmprMax;
SIG_GROUP_ 1649 mVehBattStat 1 : CellTmprMin MsgCrc MsgCntr BattSocFast;
SIG_GROUP_ 1648 mVIN 1 : VIN_Char13 VIN_Char12 VIN_Char11 VIN_Char10 VIN_Char14 VIN_Char15 VIN_Char16 VIN_Char17;
SIG_GROUP_ 1024 mTCLeftJoyStat 1 : Left_Trigger MsgCrc MsgCntr Btn_Dwn Btn_Left Btn_Right Btn_Up LeftX_Neg LeftX_Ntrl LeftX_Pos LeftX_Value LeftY_Neg LeftY_Ntrl LeftY_Pos LeftY_Value;
SIG_GROUP_ 1026 mTCRightJoyStat 1 : MsgCrc MsgCntr Right_Trigger RightY_Value RightY_Pos RightY_Ntrl RightY_Neg RightX_Value RightX_Pos RightX_Ntrl RightX_Neg Btn_4 Btn_3 Btn_2 Btn_1;
SIG_GROUP_ 289 mVehCtrlTORq 1 : MsgCntr TO_Accel_Cmd TO_Steer_Cmd TO_EstopRq MsgCrc;
SIG_GROUP_ 288 mTOStat 1 : MsgCntr MsgCrc VehDirCmd TO_dlg_resp_code TO_dlg_resp_id TO_ConnectionStat TO_cmd_veh_mode;
SIG_GROUP_ 1920 UUDT_Resp 1 : UUDT_Byte_7 UUDT_Byte_6 UUDT_Byte_5 UUDT_Byte_4 UUDT_Byte_3 UUDT_Byte_2 UUDT_Byte_1 UUDT_Byte_0;
SIG_GROUP_ 1952 mDiagRq_VCU 1 : Diag_Byte_7 Diag_Byte_6 Diag_Byte_5 Diag_Byte_4 Diag_Byte_3 Diag_Byte_2 Diag_Byte_1 Diag_Byte_0;
SIG_GROUP_ 1160 mVcuHeartbeat 1 : seconds nanoseconds;
SIG_GROUP_ 1368 mCgmFaults 1 : vcu_connection_fault to_connection_fault modem_teleops_3_fault modem_teleops_2_fault modem_teleops_1_fault modem_telematics_fault gps_sensor_fault fms_connection_fault adcu_ros_bridge_fault adcu_grpc_bridge_fault;
SIG_GROUP_ 528 mCgmHeartbeat 1 : seconds nanoseconds;
SIG_GROUP_ 1367 mCgmSwVer 1 : SwStat SwRev SwMin SwMaj;
SIG_GROUP_ 772 mVehSwVers 1 : EPB_SwRev EPB_SwMin Ebcm2L_SwVerStat Ebcm2L_SwVerRev AVAS_SwMin AVAS_SwMaj Ebcm2L_SwVerMin Ebcm1U_SwVerMin Ebcm2L_SwVerMaj Ebcm1U_SwVerMaj EPB_SwMaj Ebcm1U_SwVerStat Ebcm1U_SwVerRev;
SIG_GROUP_ 290 mVehFdbkTO 1 : MsgCrc MsgCntr VCU_dlg_msg_rq EstopDetected TO_Steer_Fdbk;
SIG_GROUP_ 1555 mAdcuStat 1 : AdcuStatus AdcuShtdwnRdy AdcuEstopRq MsgCrc MsgCntr TO_Assistance_Rq AD_Ready AD_Mission_Cmplt;
SIG_GROUP_ 1554 mExtLightsTORq 1 : LightTurnCmdR LightTurnCmdL LightHighCmd HornCmd LightHazardCmd MsgCrc MsgCntr;
SIG_GROUP_ 1793 mAdcuSwVer 1 : SwStat SwRev SwMin SwMaj;
SIG_GROUP_ 516 mVcuFaults 1 : Flt_LocTo Flt_Bay2Pwr12v Flt_WriteEeprom Flt_ImuSns Flt_LocFcmCan Flt_LocBe Flt_ImuRst Flt_LocEbcm1 Flt_12vSys Flt_Keypad4 Flt_LocVsc Flt_LocAdcu Flt_LocLrr Flt_KeypadC Flt_Bay1BeltSns Flt_Bay1Mtr Flt_Bay1MtrPos Flt_Bay2Mtr Flt_Bay2MtrPos Flt_Bay1Pwr12v Flt_Bay2BeltSns Flt_KeypadLight Flt_BrkSafeSys Flt_LocEbcm2 Flt_SafeCircuit Flt_LocEss Flt_MstrSwitch Flt_LocAVAS Flt_EpbSys Flt_SafeExtLight Flt_SafeProp Flt_WhdEnbl Flt_CntctrStat Flt_BrkPrsr Flt_SbwEnbl Flt_LocSbw Flt_48Volt Flt_12Volt Flt_LocTc Flt_LocWhd Flt_DcdcEnbl Flt_SafeSteer Flt_ReadEeprom Flt_LocEpb Flt_InvalidGearRq;
SIG_GROUP_ 514 mVehState 1 : SBW_RtEndStopReached SBW_LfEndStopReached Invld_GearRq EstopDetected Tether_Connected VehParkRq ArbVehSpdValid ArbVehSpd GearRq GearChangeParkAllow TO_Allowed LOS_Allowed AD_Allowed GearChangeDrvRevAllow GearAct MsgCrc MsgCntr VehDte LvVolt CrashSns VcuEstopSns VehState;
SIG_GROUP_ 512 mExtLightStat 1 : MsgCntr LightTurnRearRStat LightTurnRearLStat LightTurnFrontRStat LightTurnFrontLStat LightHighStat LightLow_TailStat LightDRLStat LightStopStat LightChmslStat LightRevStat HornStat;
SIG_GROUP_ 2634005196 mVcuVehID 1 : VehId_Char8 VehId_Char7 VehId_Char6 VehId_Char5 VehId_Char4 VehId_Char3 VehId_Char2 VehId_Char1;
SIG_GROUP_ 2634009804 mVcuSwVer 1 : SwStat SwRev SwMin SwMaj;
